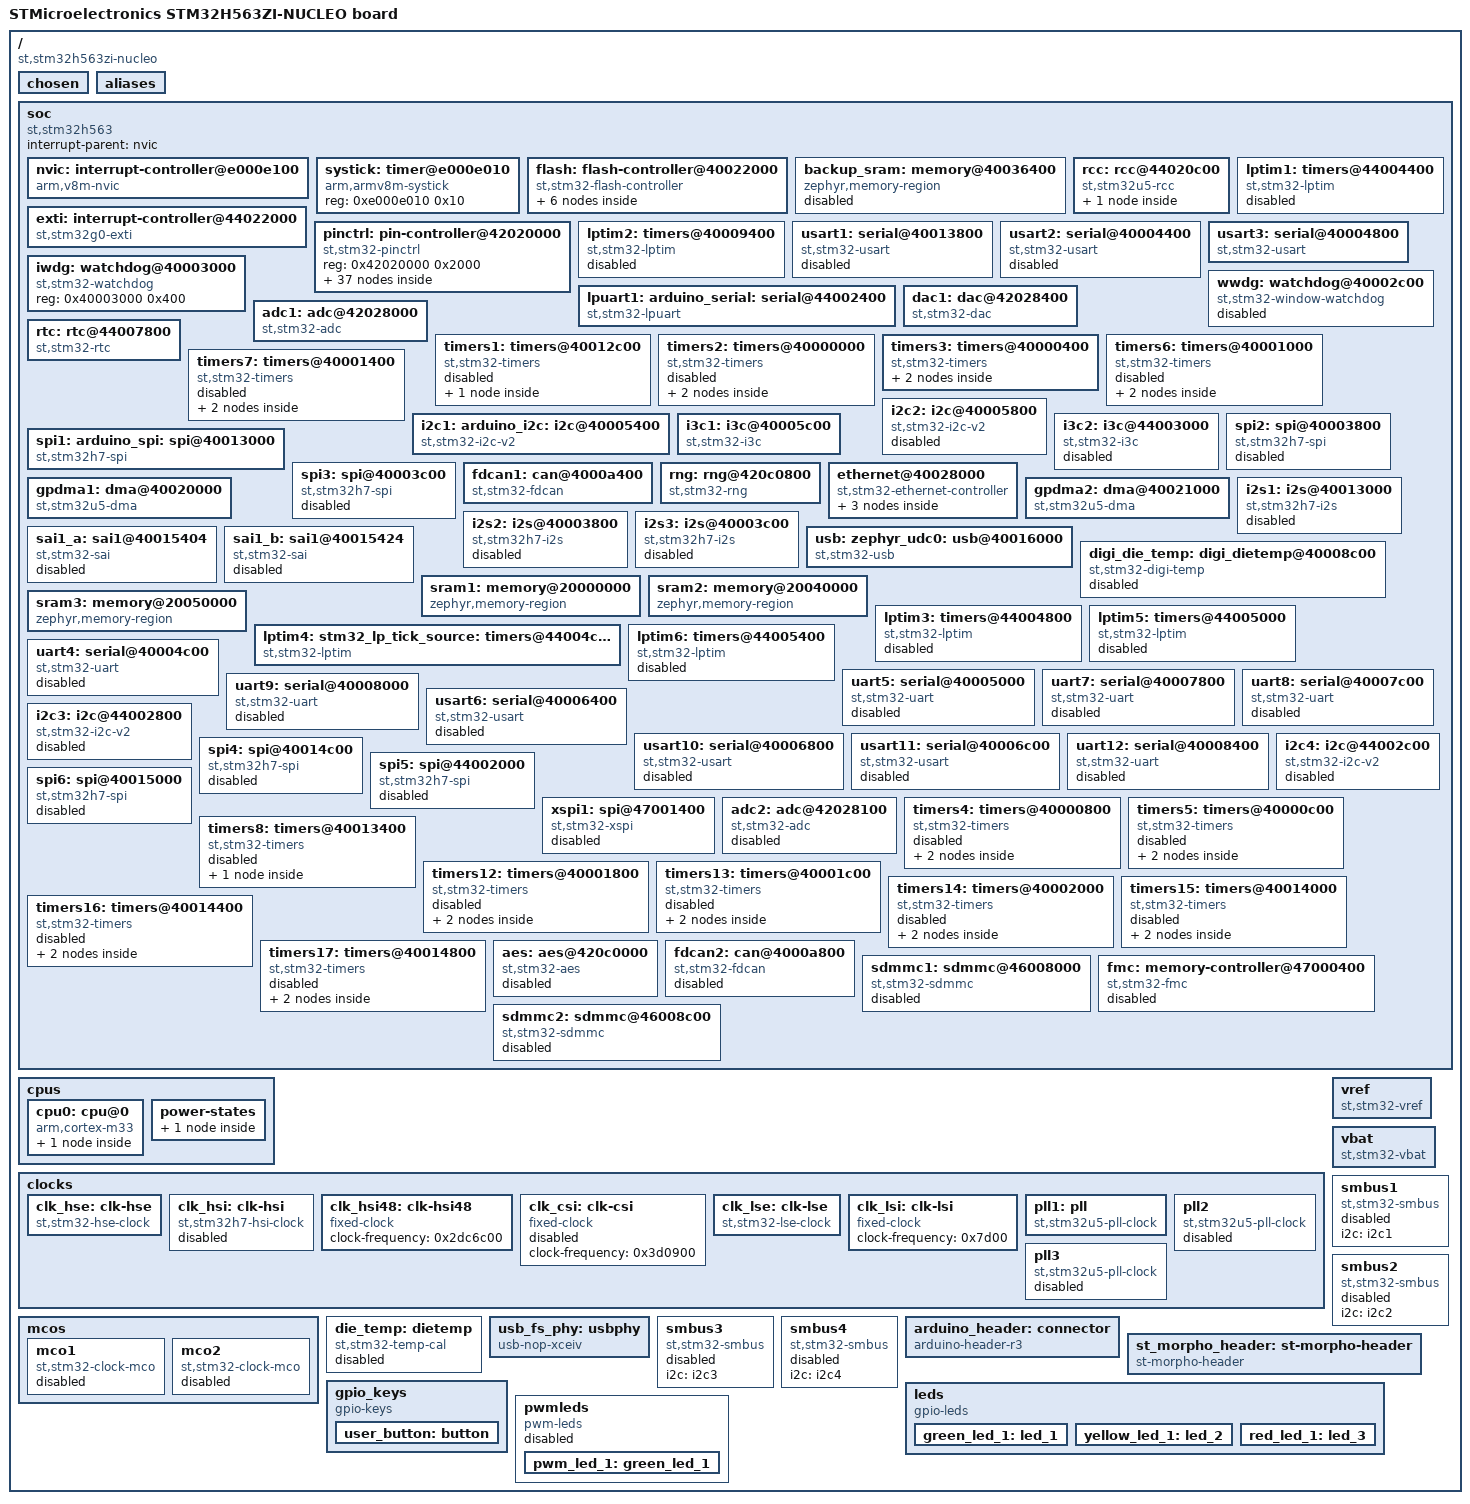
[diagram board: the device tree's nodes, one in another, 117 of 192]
/dts-v1/;

/* node '/' defined in zephyr/dts/common/skeleton.dtsi:9 */
/ {
	model = "STMicroelectronics STM32H563ZI-NUCLEO board"; /* in zephyr/boards/st/nucleo_h563zi/nucleo_h563zi.dts:13 */
	compatible = "st,stm32h563zi-nucleo";                  /* in zephyr/boards/st/nucleo_h563zi/nucleo_h563zi.dts:14 */
	#address-cells = < 0x1 >;                              /* in zephyr/boards/st/nucleo_h563zi/nucleo_h563zi.dts:16 */
	#size-cells = < 0x1 >;                                 /* in zephyr/boards/st/nucleo_h563zi/nucleo_h563zi.dts:17 */

	/* node '/chosen' defined in zephyr/dts/common/skeleton.dtsi:12 */
	chosen {
		zephyr,flash-controller = &flash;         /* in zephyr/dts/arm/st/h5/stm32h5.dtsi:21 */
		zephyr,entropy = &rng;                    /* in zephyr/dts/arm/st/h5/stm32h5.dtsi:22 */
		zephyr,console = &usart3;                 /* in zephyr/boards/st/nucleo_h563zi/nucleo_h563zi.dts:20 */
		zephyr,shell-uart = &usart3;              /* in zephyr/boards/st/nucleo_h563zi/nucleo_h563zi.dts:21 */
		zephyr,sram = &sram1;                     /* in zephyr/boards/st/nucleo_h563zi/nucleo_h563zi.dts:22 */
		zephyr,flash = &flash0;                   /* in zephyr/boards/st/nucleo_h563zi/nucleo_h563zi.dts:23 */
		zephyr,code-partition = &slot0_partition; /* in zephyr/boards/st/nucleo_h563zi/nucleo_h563zi.dts:24 */
		zephyr,canbus = &fdcan1;                  /* in zephyr/boards/st/nucleo_h563zi/nucleo_h563zi.dts:25 */
	};

	/* node '/aliases' defined in zephyr/dts/common/skeleton.dtsi:13 */
	aliases {
		led0 = &green_led_1;   /* in zephyr/boards/st/nucleo_h563zi/nucleo_h563zi.dts:29 */
		sw0 = &user_button;    /* in zephyr/boards/st/nucleo_h563zi/nucleo_h563zi.dts:30 */
		watchdog0 = &iwdg;     /* in zephyr/boards/st/nucleo_h563zi/nucleo_h563zi.dts:31 */
		pwm-led0 = &pwm_led_1; /* in zephyr/boards/st/nucleo_h563zi/nucleo_h563zi.dts:32 */
		volt-sensor0 = &vref;  /* in zephyr/boards/st/nucleo_h563zi/nucleo_h563zi.dts:33 */
		volt-sensor1 = &vbat;  /* in zephyr/boards/st/nucleo_h563zi/nucleo_h563zi.dts:34 */
	};

	/* node '/soc' defined in zephyr/dts/arm/armv8-m.dtsi:6 */
	soc {
		#address-cells = < 0x1 >;     /* in zephyr/dts/arm/armv8-m.dtsi:7 */
		#size-cells = < 0x1 >;        /* in zephyr/dts/arm/armv8-m.dtsi:8 */
		interrupt-parent = < &nvic >; /* in zephyr/dts/arm/armv8-m.dtsi:10 */
		ranges;                       /* in zephyr/dts/arm/armv8-m.dtsi:11 */
		compatible = "st,stm32h563",
		             "st,stm32h5",
		             "simple-bus";    /* in zephyr/dts/arm/st/h5/stm32h563.dtsi:11 */

		/* node '/soc/interrupt-controller@e000e100' defined in zephyr/dts/arm/armv8-m.dtsi:13 */
		nvic: interrupt-controller@e000e100 {
			#address-cells = < 0x1 >;            /* in zephyr/dts/arm/armv8-m.dtsi:14 */
			compatible = "arm,v8m-nvic";         /* in zephyr/dts/arm/armv8-m.dtsi:15 */
			reg = < 0xe000e100 0xc00 >;          /* in zephyr/dts/arm/armv8-m.dtsi:16 */
			interrupt-controller;                /* in zephyr/dts/arm/armv8-m.dtsi:17 */
			#interrupt-cells = < 0x2 >;          /* in zephyr/dts/arm/armv8-m.dtsi:18 */
			arm,num-irq-priority-bits = < 0x4 >; /* in zephyr/dts/arm/st/h5/stm32h5.dtsi:733 */
			phandle = < 0x1 >;                   /* in zephyr/dts/arm/armv8-m.dtsi:10 */
		};

		/* node '/soc/timer@e000e010' defined in zephyr/dts/arm/armv8-m.dtsi:21 */
		systick: timer@e000e010 {
			compatible = "arm,armv8m-systick"; /* in zephyr/dts/arm/armv8-m.dtsi:22 */
			reg = < 0xe000e010 0x10 >;         /* in zephyr/dts/arm/armv8-m.dtsi:23 */
		};

		/* node '/soc/flash-controller@40022000' defined in zephyr/dts/arm/st/h5/stm32h5.dtsi:123 */
		flash: flash-controller@40022000 {
			compatible = "st,stm32-flash-controller",
			             "st,stm32l5-flash-controller"; /* in zephyr/dts/arm/st/h5/stm32h5.dtsi:124 */
			reg = < 0x40022000 0x400 >;                 /* in zephyr/dts/arm/st/h5/stm32h5.dtsi:125 */
			interrupts = < 0x6 0x0 >;                   /* in zephyr/dts/arm/st/h5/stm32h5.dtsi:126 */
			#address-cells = < 0x1 >;                   /* in zephyr/dts/arm/st/h5/stm32h5.dtsi:128 */
			#size-cells = < 0x1 >;                      /* in zephyr/dts/arm/st/h5/stm32h5.dtsi:129 */

			/* node '/soc/flash-controller@40022000/flash@8000000' defined in zephyr/dts/arm/st/h5/stm32h5.dtsi:131 */
			flash0: flash@8000000 {
				compatible = "st,stm32-nv-flash",
				             "soc-nv-flash";      /* in zephyr/dts/arm/st/h5/stm32h5.dtsi:132 */
				write-block-size = < 0x10 >;      /* in zephyr/dts/arm/st/h5/stm32h5.dtsi:134 */
				erase-block-size = < 0x2000 >;    /* in zephyr/dts/arm/st/h5/stm32h5.dtsi:135 */
				max-erase-time = < 0xa >;         /* in zephyr/dts/arm/st/h5/stm32h5.dtsi:137 */
				reg = < 0x8000000 0x200000 >;     /* in zephyr/dts/arm/st/h5/stm32h563Xi.dtsi:14 */

				/* node '/soc/flash-controller@40022000/flash@8000000/partitions' defined in zephyr/boards/st/nucleo_h563zi/nucleo_h563zi-common.dtsi:178 */
				partitions {
					compatible = "fixed-partitions"; /* in zephyr/boards/st/nucleo_h563zi/nucleo_h563zi-common.dtsi:179 */
					#address-cells = < 0x1 >;        /* in zephyr/boards/st/nucleo_h563zi/nucleo_h563zi-common.dtsi:180 */
					#size-cells = < 0x1 >;           /* in zephyr/boards/st/nucleo_h563zi/nucleo_h563zi-common.dtsi:181 */

					/* node '/soc/flash-controller@40022000/flash@8000000/partitions/partition@0' defined in zephyr/boards/st/nucleo_h563zi/nucleo_h563zi-common.dtsi:183 */
					boot_partition: partition@0 {
						label = "mcuboot";     /* in zephyr/boards/st/nucleo_h563zi/nucleo_h563zi-common.dtsi:184 */
						reg = < 0x0 0x10000 >; /* in zephyr/boards/st/nucleo_h563zi/nucleo_h563zi-common.dtsi:185 */
					};

					/* node '/soc/flash-controller@40022000/flash@8000000/partitions/partition@10000' defined in zephyr/boards/st/nucleo_h563zi/nucleo_h563zi-common.dtsi:188 */
					slot0_partition: partition@10000 {
						label = "image-0";         /* in zephyr/boards/st/nucleo_h563zi/nucleo_h563zi-common.dtsi:189 */
						reg = < 0x10000 0xf0000 >; /* in zephyr/boards/st/nucleo_h563zi/nucleo_h563zi-common.dtsi:190 */
					};

					/* node '/soc/flash-controller@40022000/flash@8000000/partitions/partition@100000' defined in zephyr/boards/st/nucleo_h563zi/nucleo_h563zi-common.dtsi:193 */
					slot1_partition: partition@100000 {
						label = "image-1";          /* in zephyr/boards/st/nucleo_h563zi/nucleo_h563zi-common.dtsi:194 */
						reg = < 0x100000 0xf0000 >; /* in zephyr/boards/st/nucleo_h563zi/nucleo_h563zi-common.dtsi:195 */
					};

					/* node '/soc/flash-controller@40022000/flash@8000000/partitions/partition@1f0000' defined in zephyr/boards/st/nucleo_h563zi/nucleo_h563zi-common.dtsi:198 */
					storage_partition: partition@1f0000 {
						label = "storage";          /* in zephyr/boards/st/nucleo_h563zi/nucleo_h563zi-common.dtsi:199 */
						reg = < 0x1f0000 0x10000 >; /* in zephyr/boards/st/nucleo_h563zi/nucleo_h563zi-common.dtsi:200 */
					};
				};
			};
		};

		/* node '/soc/memory@40036400' defined in zephyr/dts/arm/st/h5/stm32h5.dtsi:141 */
		backup_sram: memory@40036400 {
			compatible = "zephyr,memory-region",
			             "st,stm32-backup-sram";  /* in zephyr/dts/arm/st/h5/stm32h5.dtsi:142 */
			clocks = < &rcc 0x88 0x10000000 >;    /* in zephyr/dts/arm/st/h5/stm32h5.dtsi:144 */
			zephyr,memory-region = "BACKUP_SRAM"; /* in zephyr/dts/arm/st/h5/stm32h5.dtsi:145 */
			status = "disabled";                  /* in zephyr/dts/arm/st/h5/stm32h5.dtsi:146 */
			reg = < 0x40036400 0x1000 >;          /* in zephyr/dts/arm/st/h5/stm32h562.dtsi:79 */
		};

		/* node '/soc/rcc@44020c00' defined in zephyr/dts/arm/st/h5/stm32h5.dtsi:149 */
		rcc: rcc@44020c00 {
			compatible = "st,stm32u5-rcc";   /* in zephyr/dts/arm/st/h5/stm32h5.dtsi:150 */
			clocks-controller;               /* in zephyr/dts/arm/st/h5/stm32h5.dtsi:151 */
			#clock-cells = < 0x2 >;          /* in zephyr/dts/arm/st/h5/stm32h5.dtsi:152 */
			reg = < 0x44020c00 0x400 >;      /* in zephyr/dts/arm/st/h5/stm32h5.dtsi:153 */
			clocks = < &pll >;               /* in zephyr/boards/st/nucleo_h563zi/nucleo_h563zi-common.dtsi:93 */
			clock-frequency = < 0xe4e1c00 >; /* in zephyr/boards/st/nucleo_h563zi/nucleo_h563zi-common.dtsi:94 */
			ahb-prescaler = < 0x1 >;         /* in zephyr/boards/st/nucleo_h563zi/nucleo_h563zi-common.dtsi:95 */
			apb1-prescaler = < 0x2 >;        /* in zephyr/boards/st/nucleo_h563zi/nucleo_h563zi-common.dtsi:96 */
			apb2-prescaler = < 0x1 >;        /* in zephyr/boards/st/nucleo_h563zi/nucleo_h563zi-common.dtsi:97 */
			apb3-prescaler = < 0x2 >;        /* in zephyr/boards/st/nucleo_h563zi/nucleo_h563zi-common.dtsi:98 */
			phandle = < 0x2 >;               /* in zephyr/dts/arm/st/h5/stm32h5.dtsi:144 */

			/* node '/soc/rcc@44020c00/reset-controller' defined in zephyr/dts/arm/st/h5/stm32h5.dtsi:155 */
			rctl: reset-controller {
				compatible = "st,stm32-rcc-rctl"; /* in zephyr/dts/arm/st/h5/stm32h5.dtsi:156 */
				#reset-cells = < 0x1 >;           /* in zephyr/dts/arm/st/h5/stm32h5.dtsi:157 */
				phandle = < 0x4 >;                /* in zephyr/dts/arm/st/h5/stm32h5.dtsi:256 */
			};
		};

		/* node '/soc/interrupt-controller@44022000' defined in zephyr/dts/arm/st/h5/stm32h5.dtsi:161 */
		exti: interrupt-controller@44022000 {
			compatible = "st,stm32g0-exti",
			             "st,stm32-exti";   /* in zephyr/dts/arm/st/h5/stm32h5.dtsi:162 */
			interrupt-controller;           /* in zephyr/dts/arm/st/h5/stm32h5.dtsi:163 */
			#interrupt-cells = < 0x1 >;     /* in zephyr/dts/arm/st/h5/stm32h5.dtsi:164 */
			#address-cells = < 0x1 >;       /* in zephyr/dts/arm/st/h5/stm32h5.dtsi:165 */
			reg = < 0x44022000 0x400 >;     /* in zephyr/dts/arm/st/h5/stm32h5.dtsi:166 */
			clocks = < &rcc 0xa8 0x2 >;     /* in zephyr/dts/arm/st/h5/stm32h5.dtsi:167 */
			num-lines = < 0x40 >;           /* in zephyr/dts/arm/st/h5/stm32h5.dtsi:168 */
			interrupts = < 0xb 0x0 >,
			             < 0xc 0x0 >,
			             < 0xd 0x0 >,
			             < 0xe 0x0 >,
			             < 0xf 0x0 >,
			             < 0x10 0x0 >,
			             < 0x11 0x0 >,
			             < 0x12 0x0 >,
			             < 0x13 0x0 >,
			             < 0x14 0x0 >,
			             < 0x15 0x0 >,
			             < 0x16 0x0 >,
			             < 0x17 0x0 >,
			             < 0x18 0x0 >,
			             < 0x19 0x0 >,
			             < 0x1a 0x0 >;      /* in zephyr/dts/arm/st/h5/stm32h5.dtsi:169 */
			interrupt-names = "line0",
			                  "line1",
			                  "line2",
			                  "line3",
			                  "line4",
			                  "line5",
			                  "line6",
			                  "line7",
			                  "line8",
			                  "line9",
			                  "line10",
			                  "line11",
			                  "line12",
			                  "line13",
			                  "line14",
			                  "line15";     /* in zephyr/dts/arm/st/h5/stm32h5.dtsi:173 */
			line-ranges = < 0x0 0x1 >,
			              < 0x1 0x1 >,
			              < 0x2 0x1 >,
			              < 0x3 0x1 >,
			              < 0x4 0x1 >,
			              < 0x5 0x1 >,
			              < 0x6 0x1 >,
			              < 0x7 0x1 >,
			              < 0x8 0x1 >,
			              < 0x9 0x1 >,
			              < 0xa 0x1 >,
			              < 0xb 0x1 >,
			              < 0xc 0x1 >,
			              < 0xd 0x1 >,
			              < 0xe 0x1 >,
			              < 0xf 0x1 >;      /* in zephyr/dts/arm/st/h5/stm32h5.dtsi:177 */
		};

		/* node '/soc/pin-controller@42020000' defined in zephyr/dts/arm/st/h5/stm32h5.dtsi:183 */
		pinctrl: pin-controller@42020000 {
			compatible = "st,stm32-pinctrl"; /* in zephyr/dts/arm/st/h5/stm32h5.dtsi:184 */
			#address-cells = < 0x1 >;        /* in zephyr/dts/arm/st/h5/stm32h5.dtsi:185 */
			#size-cells = < 0x1 >;           /* in zephyr/dts/arm/st/h5/stm32h5.dtsi:186 */
			reg = < 0x42020000 0x2000 >;     /* in zephyr/dts/arm/st/h5/stm32h5.dtsi:187 */

			/* node '/soc/pin-controller@42020000/gpio@42020000' defined in zephyr/dts/arm/st/h5/stm32h5.dtsi:189 */
			gpioa: gpio@42020000 {
				compatible = "st,stm32-gpio"; /* in zephyr/dts/arm/st/h5/stm32h5.dtsi:190 */
				gpio-controller;              /* in zephyr/dts/arm/st/h5/stm32h5.dtsi:191 */
				#gpio-cells = < 0x2 >;        /* in zephyr/dts/arm/st/h5/stm32h5.dtsi:192 */
				reg = < 0x42020000 0x400 >;   /* in zephyr/dts/arm/st/h5/stm32h5.dtsi:193 */
				clocks = < &rcc 0x8c 0x1 >;   /* in zephyr/dts/arm/st/h5/stm32h5.dtsi:194 */
				phandle = < 0x2c >;           /* in zephyr/boards/st/nucleo_h563zi/arduino_r3_connector.dtsi:14 */
			};

			/* node '/soc/pin-controller@42020000/gpio@42020400' defined in zephyr/dts/arm/st/h5/stm32h5.dtsi:197 */
			gpiob: gpio@42020400 {
				compatible = "st,stm32-gpio"; /* in zephyr/dts/arm/st/h5/stm32h5.dtsi:198 */
				gpio-controller;              /* in zephyr/dts/arm/st/h5/stm32h5.dtsi:199 */
				#gpio-cells = < 0x2 >;        /* in zephyr/dts/arm/st/h5/stm32h5.dtsi:200 */
				reg = < 0x42020400 0x400 >;   /* in zephyr/dts/arm/st/h5/stm32h5.dtsi:201 */
				clocks = < &rcc 0x8c 0x2 >;   /* in zephyr/dts/arm/st/h5/stm32h5.dtsi:202 */
				phandle = < 0x2e >;           /* in zephyr/boards/st/nucleo_h563zi/arduino_r3_connector.dtsi:14 */
			};

			/* node '/soc/pin-controller@42020000/gpio@42020800' defined in zephyr/dts/arm/st/h5/stm32h5.dtsi:205 */
			gpioc: gpio@42020800 {
				compatible = "st,stm32-gpio"; /* in zephyr/dts/arm/st/h5/stm32h5.dtsi:206 */
				gpio-controller;              /* in zephyr/dts/arm/st/h5/stm32h5.dtsi:207 */
				#gpio-cells = < 0x2 >;        /* in zephyr/dts/arm/st/h5/stm32h5.dtsi:208 */
				reg = < 0x42020800 0x400 >;   /* in zephyr/dts/arm/st/h5/stm32h5.dtsi:209 */
				clocks = < &rcc 0x8c 0x4 >;   /* in zephyr/dts/arm/st/h5/stm32h5.dtsi:210 */
				phandle = < 0x2d >;           /* in zephyr/boards/st/nucleo_h563zi/arduino_r3_connector.dtsi:14 */
			};

			/* node '/soc/pin-controller@42020000/gpio@42020c00' defined in zephyr/dts/arm/st/h5/stm32h5.dtsi:213 */
			gpiod: gpio@42020c00 {
				compatible = "st,stm32-gpio"; /* in zephyr/dts/arm/st/h5/stm32h5.dtsi:214 */
				gpio-controller;              /* in zephyr/dts/arm/st/h5/stm32h5.dtsi:215 */
				#gpio-cells = < 0x2 >;        /* in zephyr/dts/arm/st/h5/stm32h5.dtsi:216 */
				reg = < 0x42020c00 0x400 >;   /* in zephyr/dts/arm/st/h5/stm32h5.dtsi:217 */
				clocks = < &rcc 0x8c 0x8 >;   /* in zephyr/dts/arm/st/h5/stm32h5.dtsi:218 */
				phandle = < 0x14 >;           /* in zephyr/boards/st/nucleo_h563zi/nucleo_h563zi-common.dtsi:118 */
			};

			/* node '/soc/pin-controller@42020000/gpio@42021c00' defined in zephyr/dts/arm/st/h5/stm32h5.dtsi:221 */
			gpioh: gpio@42021c00 {
				compatible = "st,stm32-gpio"; /* in zephyr/dts/arm/st/h5/stm32h5.dtsi:222 */
				gpio-controller;              /* in zephyr/dts/arm/st/h5/stm32h5.dtsi:223 */
				#gpio-cells = < 0x2 >;        /* in zephyr/dts/arm/st/h5/stm32h5.dtsi:224 */
				reg = < 0x42021c00 0x400 >;   /* in zephyr/dts/arm/st/h5/stm32h5.dtsi:225 */
				clocks = < &rcc 0x8c 0x80 >;  /* in zephyr/dts/arm/st/h5/stm32h5.dtsi:226 */
				phandle = < 0x32 >;           /* in zephyr/boards/st/nucleo_h563zi/st_morpho_connector.dtsi:15 */
			};

			/* node '/soc/pin-controller@42020000/gpio@42021000' defined in zephyr/dts/arm/st/h5/stm32h562.dtsi:27 */
			gpioe: gpio@42021000 {
				compatible = "st,stm32-gpio"; /* in zephyr/dts/arm/st/h5/stm32h562.dtsi:28 */
				gpio-controller;              /* in zephyr/dts/arm/st/h5/stm32h562.dtsi:29 */
				#gpio-cells = < 0x2 >;        /* in zephyr/dts/arm/st/h5/stm32h562.dtsi:30 */
				reg = < 0x42021000 0x400 >;   /* in zephyr/dts/arm/st/h5/stm32h562.dtsi:31 */
				clocks = < &rcc 0x8c 0x10 >;  /* in zephyr/dts/arm/st/h5/stm32h562.dtsi:32 */
				phandle = < 0x31 >;           /* in zephyr/boards/st/nucleo_h563zi/arduino_r3_connector.dtsi:14 */
			};

			/* node '/soc/pin-controller@42020000/gpio@42021400' defined in zephyr/dts/arm/st/h5/stm32h562.dtsi:35 */
			gpiof: gpio@42021400 {
				compatible = "st,stm32-gpio"; /* in zephyr/dts/arm/st/h5/stm32h562.dtsi:36 */
				gpio-controller;              /* in zephyr/dts/arm/st/h5/stm32h562.dtsi:37 */
				#gpio-cells = < 0x2 >;        /* in zephyr/dts/arm/st/h5/stm32h562.dtsi:38 */
				reg = < 0x42021400 0x400 >;   /* in zephyr/dts/arm/st/h5/stm32h562.dtsi:39 */
				clocks = < &rcc 0x8c 0x20 >;  /* in zephyr/dts/arm/st/h5/stm32h562.dtsi:40 */
				phandle = < 0x2f >;           /* in zephyr/boards/st/nucleo_h563zi/arduino_r3_connector.dtsi:14 */
			};

			/* node '/soc/pin-controller@42020000/gpio@42021800' defined in zephyr/dts/arm/st/h5/stm32h562.dtsi:43 */
			gpiog: gpio@42021800 {
				compatible = "st,stm32-gpio"; /* in zephyr/dts/arm/st/h5/stm32h562.dtsi:44 */
				gpio-controller;              /* in zephyr/dts/arm/st/h5/stm32h562.dtsi:45 */
				#gpio-cells = < 0x2 >;        /* in zephyr/dts/arm/st/h5/stm32h562.dtsi:46 */
				reg = < 0x42021800 0x400 >;   /* in zephyr/dts/arm/st/h5/stm32h562.dtsi:47 */
				clocks = < &rcc 0x8c 0x40 >;  /* in zephyr/dts/arm/st/h5/stm32h562.dtsi:48 */
				phandle = < 0x30 >;           /* in zephyr/boards/st/nucleo_h563zi/arduino_r3_connector.dtsi:14 */
			};

			/* node '/soc/pin-controller@42020000/gpio@42022000' defined in zephyr/dts/arm/st/h5/stm32h562.dtsi:51 */
			gpioi: gpio@42022000 {
				compatible = "st,stm32-gpio"; /* in zephyr/dts/arm/st/h5/stm32h562.dtsi:52 */
				gpio-controller;              /* in zephyr/dts/arm/st/h5/stm32h562.dtsi:53 */
				#gpio-cells = < 0x2 >;        /* in zephyr/dts/arm/st/h5/stm32h562.dtsi:54 */
				reg = < 0x42022000 0x400 >;   /* in zephyr/dts/arm/st/h5/stm32h562.dtsi:55 */
				clocks = < &rcc 0x8c 0x100 >; /* in zephyr/dts/arm/st/h5/stm32h562.dtsi:56 */
			};

			/* node '/soc/pin-controller@42020000/adc1_inp15_pa3' defined in modules/hal/stm32/dts/st/h5/stm32h563zitx-pinctrl.dtsi:31 */
			adc1_inp15_pa3: adc1_inp15_pa3 {
				pinmux = < 0x70 >; /* in modules/hal/stm32/dts/st/h5/stm32h563zitx-pinctrl.dtsi:32 */
				phandle = < 0xb >; /* in zephyr/boards/st/nucleo_h563zi/nucleo_h563zi-common.dtsi:161 */
			};

			/* node '/soc/pin-controller@42020000/adc1_inp3_pa6' defined in modules/hal/stm32/dts/st/h5/stm32h563zitx-pinctrl.dtsi:47 */
			adc1_inp3_pa6: adc1_inp3_pa6 {
				pinmux = < 0xd0 >; /* in modules/hal/stm32/dts/st/h5/stm32h563zitx-pinctrl.dtsi:48 */
				phandle = < 0xa >; /* in zephyr/boards/st/nucleo_h563zi/nucleo_h563zi-common.dtsi:161 */
			};

			/* node '/soc/pin-controller@42020000/dac1_out2_pa5' defined in modules/hal/stm32/dts/st/h5/stm32h563zitx-pinctrl.dtsi:687 */
			dac1_out2_pa5: dac1_out2_pa5 {
				pinmux = < 0xb0 >; /* in modules/hal/stm32/dts/st/h5/stm32h563zitx-pinctrl.dtsi:688 */
				phandle = < 0x9 >; /* in zephyr/boards/st/nucleo_h563zi/nucleo_h563zi-common.dtsi:153 */
			};

			/* node '/soc/pin-controller@42020000/eth_ref_clk_pa1' defined in modules/hal/stm32/dts/st/h5/stm32h563zitx-pinctrl.dtsi:895 */
			eth_ref_clk_pa1: eth_ref_clk_pa1 {
				pinmux = < 0x2b >;             /* in modules/hal/stm32/dts/st/h5/stm32h563zitx-pinctrl.dtsi:896 */
				slew-rate = "very-high-speed"; /* in modules/hal/stm32/dts/st/h5/stm32h563zitx-pinctrl.dtsi:897 */
				phandle = < 0x19 >;            /* in zephyr/boards/st/nucleo_h563zi/nucleo_h563zi.dts:44 */
			};

			/* node '/soc/pin-controller@42020000/eth_mdio_pa2' defined in modules/hal/stm32/dts/st/h5/stm32h563zitx-pinctrl.dtsi:905 */
			eth_mdio_pa2: eth_mdio_pa2 {
				pinmux = < 0x4b >;             /* in modules/hal/stm32/dts/st/h5/stm32h563zitx-pinctrl.dtsi:906 */
				slew-rate = "very-high-speed"; /* in modules/hal/stm32/dts/st/h5/stm32h563zitx-pinctrl.dtsi:907 */
				phandle = < 0x1f >;            /* in zephyr/boards/st/nucleo_h563zi/nucleo_h563zi.dts:58 */
			};

			/* node '/soc/pin-controller@42020000/eth_crs_dv_pa7' defined in modules/hal/stm32/dts/st/h5/stm32h563zitx-pinctrl.dtsi:920 */
			eth_crs_dv_pa7: eth_crs_dv_pa7 {
				pinmux = < 0xeb >;             /* in modules/hal/stm32/dts/st/h5/stm32h563zitx-pinctrl.dtsi:921 */
				slew-rate = "very-high-speed"; /* in modules/hal/stm32/dts/st/h5/stm32h563zitx-pinctrl.dtsi:922 */
				phandle = < 0x1a >;            /* in zephyr/boards/st/nucleo_h563zi/nucleo_h563zi.dts:44 */
			};

			/* node '/soc/pin-controller@42020000/eth_txd1_pb15' defined in modules/hal/stm32/dts/st/h5/stm32h563zitx-pinctrl.dtsi:960 */
			eth_txd1_pb15: eth_txd1_pb15 {
				pinmux = < 0x3eb >;            /* in modules/hal/stm32/dts/st/h5/stm32h563zitx-pinctrl.dtsi:961 */
				slew-rate = "very-high-speed"; /* in modules/hal/stm32/dts/st/h5/stm32h563zitx-pinctrl.dtsi:962 */
				phandle = < 0x1d >;            /* in zephyr/boards/st/nucleo_h563zi/nucleo_h563zi.dts:44 */
			};

			/* node '/soc/pin-controller@42020000/eth_mdc_pc1' defined in modules/hal/stm32/dts/st/h5/stm32h563zitx-pinctrl.dtsi:965 */
			eth_mdc_pc1: eth_mdc_pc1 {
				pinmux = < 0x42b >;            /* in modules/hal/stm32/dts/st/h5/stm32h563zitx-pinctrl.dtsi:966 */
				slew-rate = "very-high-speed"; /* in modules/hal/stm32/dts/st/h5/stm32h563zitx-pinctrl.dtsi:967 */
				phandle = < 0x20 >;            /* in zephyr/boards/st/nucleo_h563zi/nucleo_h563zi.dts:58 */
			};

			/* node '/soc/pin-controller@42020000/eth_rxd0_pc4' defined in modules/hal/stm32/dts/st/h5/stm32h563zitx-pinctrl.dtsi:980 */
			eth_rxd0_pc4: eth_rxd0_pc4 {
				pinmux = < 0x48b >;            /* in modules/hal/stm32/dts/st/h5/stm32h563zitx-pinctrl.dtsi:981 */
				slew-rate = "very-high-speed"; /* in modules/hal/stm32/dts/st/h5/stm32h563zitx-pinctrl.dtsi:982 */
				phandle = < 0x17 >;            /* in zephyr/boards/st/nucleo_h563zi/nucleo_h563zi.dts:44 */
			};

			/* node '/soc/pin-controller@42020000/eth_rxd1_pc5' defined in modules/hal/stm32/dts/st/h5/stm32h563zitx-pinctrl.dtsi:985 */
			eth_rxd1_pc5: eth_rxd1_pc5 {
				pinmux = < 0x4ab >;            /* in modules/hal/stm32/dts/st/h5/stm32h563zitx-pinctrl.dtsi:986 */
				slew-rate = "very-high-speed"; /* in modules/hal/stm32/dts/st/h5/stm32h563zitx-pinctrl.dtsi:987 */
				phandle = < 0x18 >;            /* in zephyr/boards/st/nucleo_h563zi/nucleo_h563zi.dts:44 */
			};

			/* node '/soc/pin-controller@42020000/eth_tx_en_pg11' defined in modules/hal/stm32/dts/st/h5/stm32h563zitx-pinctrl.dtsi:1005 */
			eth_tx_en_pg11: eth_tx_en_pg11 {
				pinmux = < 0xd6b >;            /* in modules/hal/stm32/dts/st/h5/stm32h563zitx-pinctrl.dtsi:1006 */
				slew-rate = "very-high-speed"; /* in modules/hal/stm32/dts/st/h5/stm32h563zitx-pinctrl.dtsi:1007 */
				phandle = < 0x1b >;            /* in zephyr/boards/st/nucleo_h563zi/nucleo_h563zi.dts:44 */
			};

			/* node '/soc/pin-controller@42020000/eth_txd0_pg13' defined in modules/hal/stm32/dts/st/h5/stm32h563zitx-pinctrl.dtsi:1015 */
			eth_txd0_pg13: eth_txd0_pg13 {
				pinmux = < 0xdab >;            /* in modules/hal/stm32/dts/st/h5/stm32h563zitx-pinctrl.dtsi:1016 */
				slew-rate = "very-high-speed"; /* in modules/hal/stm32/dts/st/h5/stm32h563zitx-pinctrl.dtsi:1017 */
				phandle = < 0x1c >;            /* in zephyr/boards/st/nucleo_h563zi/nucleo_h563zi.dts:44 */
			};

			/* node '/soc/pin-controller@42020000/fdcan1_rx_pd0' defined in modules/hal/stm32/dts/st/h5/stm32h563zitx-pinctrl.dtsi:1035 */
			fdcan1_rx_pd0: fdcan1_rx_pd0 {
				pinmux = < 0x609 >; /* in modules/hal/stm32/dts/st/h5/stm32h563zitx-pinctrl.dtsi:1036 */
				phandle = < 0x15 >; /* in zephyr/boards/st/nucleo_h563zi/nucleo_h563zi-common.dtsi:169 */
			};

			/* node '/soc/pin-controller@42020000/fdcan1_tx_pd1' defined in modules/hal/stm32/dts/st/h5/stm32h563zitx-pinctrl.dtsi:1069 */
			fdcan1_tx_pd1: fdcan1_tx_pd1 {
				pinmux = < 0x629 >; /* in modules/hal/stm32/dts/st/h5/stm32h563zitx-pinctrl.dtsi:1070 */
				phandle = < 0x16 >; /* in zephyr/boards/st/nucleo_h563zi/nucleo_h563zi-common.dtsi:169 */
			};

			/* node '/soc/pin-controller@42020000/i2c1_scl_pb8' defined in modules/hal/stm32/dts/st/h5/stm32h563zitx-pinctrl.dtsi:1561 */
			i2c1_scl_pb8: i2c1_scl_pb8 {
				pinmux = < 0x304 >; /* in modules/hal/stm32/dts/st/h5/stm32h563zitx-pinctrl.dtsi:1562 */
				bias-pull-up;       /* in modules/hal/stm32/dts/st/h5/stm32h563zitx-pinctrl.dtsi:1563 */
				drive-open-drain;   /* in modules/hal/stm32/dts/st/h5/stm32h563zitx-pinctrl.dtsi:1564 */
				phandle = < 0xd >;  /* in zephyr/boards/st/nucleo_h563zi/nucleo_h563zi-common.dtsi:80 */
			};

			/* node '/soc/pin-controller@42020000/i2c1_sda_pb9' defined in modules/hal/stm32/dts/st/h5/stm32h563zitx-pinctrl.dtsi:1623 */
			i2c1_sda_pb9: i2c1_sda_pb9 {
				pinmux = < 0x324 >; /* in modules/hal/stm32/dts/st/h5/stm32h563zitx-pinctrl.dtsi:1624 */
				bias-pull-up;       /* in modules/hal/stm32/dts/st/h5/stm32h563zitx-pinctrl.dtsi:1625 */
				drive-open-drain;   /* in modules/hal/stm32/dts/st/h5/stm32h563zitx-pinctrl.dtsi:1626 */
				phandle = < 0xe >;  /* in zephyr/boards/st/nucleo_h563zi/nucleo_h563zi-common.dtsi:80 */
			};

			/* node '/soc/pin-controller@42020000/i3c1_scl_pd12' defined in modules/hal/stm32/dts/st/h5/stm32h563zitx-pinctrl.dtsi:1843 */
			i3c1_scl_pd12: i3c1_scl_pd12 {
				pinmux = < 0x785 >;            /* in modules/hal/stm32/dts/st/h5/stm32h563zitx-pinctrl.dtsi:1844 */
				slew-rate = "very-high-speed"; /* in modules/hal/stm32/dts/st/h5/stm32h563zitx-pinctrl.dtsi:1845 */
				phandle = < 0xf >;             /* in zephyr/boards/st/nucleo_h563zi/nucleo_h563zi-common.dtsi:86 */
			};

			/* node '/soc/pin-controller@42020000/i3c1_sda_pd13' defined in modules/hal/stm32/dts/st/h5/stm32h563zitx-pinctrl.dtsi:1870 */
			i3c1_sda_pd13: i3c1_sda_pd13 {
				pinmux = < 0x7a5 >;            /* in modules/hal/stm32/dts/st/h5/stm32h563zitx-pinctrl.dtsi:1871 */
				slew-rate = "very-high-speed"; /* in modules/hal/stm32/dts/st/h5/stm32h563zitx-pinctrl.dtsi:1872 */
				phandle = < 0x10 >;            /* in zephyr/boards/st/nucleo_h563zi/nucleo_h563zi-common.dtsi:86 */
			};

			/* node '/soc/pin-controller@42020000/spi1_miso_pg9' defined in modules/hal/stm32/dts/st/h5/stm32h563zitx-pinctrl.dtsi:2606 */
			spi1_miso_pg9: spi1_miso_pg9 {
				pinmux = < 0xd25 >; /* in modules/hal/stm32/dts/st/h5/stm32h563zitx-pinctrl.dtsi:2607 */
				bias-pull-down;     /* in modules/hal/stm32/dts/st/h5/stm32h563zitx-pinctrl.dtsi:2608 */
				phandle = < 0x12 >; /* in zephyr/boards/st/nucleo_h563zi/nucleo_h563zi-common.dtsi:116 */
			};

			/* node '/soc/pin-controller@42020000/spi1_mosi_pb5' defined in modules/hal/stm32/dts/st/h5/stm32h563zitx-pinctrl.dtsi:2668 */
			spi1_mosi_pb5: spi1_mosi_pb5 {
				pinmux = < 0x2a5 >; /* in modules/hal/stm32/dts/st/h5/stm32h563zitx-pinctrl.dtsi:2669 */
				bias-pull-down;     /* in modules/hal/stm32/dts/st/h5/stm32h563zitx-pinctrl.dtsi:2670 */
				phandle = < 0x13 >; /* in zephyr/boards/st/nucleo_h563zi/nucleo_h563zi-common.dtsi:116 */
			};

			/* node '/soc/pin-controller@42020000/spi1_sck_pa5' defined in modules/hal/stm32/dts/st/h5/stm32h563zitx-pinctrl.dtsi:2842 */
			spi1_sck_pa5: spi1_sck_pa5 {
				pinmux = < 0xa5 >;             /* in modules/hal/stm32/dts/st/h5/stm32h563zitx-pinctrl.dtsi:2843 */
				bias-pull-down;                /* in modules/hal/stm32/dts/st/h5/stm32h563zitx-pinctrl.dtsi:2844 */
				slew-rate = "very-high-speed"; /* in modules/hal/stm32/dts/st/h5/stm32h563zitx-pinctrl.dtsi:2845 */
				phandle = < 0x11 >;            /* in zephyr/boards/st/nucleo_h563zi/nucleo_h563zi-common.dtsi:116 */
			};

			/* node '/soc/pin-controller@42020000/tim3_ch3_pb0' defined in modules/hal/stm32/dts/st/h5/stm32h563zitx-pinctrl.dtsi:3152 */
			tim3_ch3_pb0: tim3_ch3_pb0 {
				pinmux = < 0x202 >; /* in modules/hal/stm32/dts/st/h5/stm32h563zitx-pinctrl.dtsi:3153 */
				phandle = < 0xc >;  /* in zephyr/boards/st/nucleo_h563zi/nucleo_h563zi-common.dtsi:128 */
			};

			/* node '/soc/pin-controller@42020000/lpuart1_rx_pb7' defined in modules/hal/stm32/dts/st/h5/stm32h563zitx-pinctrl.dtsi:3688 */
			lpuart1_rx_pb7: lpuart1_rx_pb7 {
				pinmux = < 0x2e8 >; /* in modules/hal/stm32/dts/st/h5/stm32h563zitx-pinctrl.dtsi:3689 */
				phandle = < 0x8 >;  /* in zephyr/boards/st/nucleo_h563zi/nucleo_h563zi-common.dtsi:102 */
			};

			/* node '/soc/pin-controller@42020000/usart3_rx_pd9' defined in modules/hal/stm32/dts/st/h5/stm32h563zitx-pinctrl.dtsi:3732 */
			usart3_rx_pd9: usart3_rx_pd9 {
				pinmux = < 0x727 >; /* in modules/hal/stm32/dts/st/h5/stm32h563zitx-pinctrl.dtsi:3733 */
				phandle = < 0x6 >;  /* in zephyr/boards/st/nucleo_h563zi/nucleo_h563zi-common.dtsi:109 */
			};

			/* node '/soc/pin-controller@42020000/lpuart1_tx_pb6' defined in modules/hal/stm32/dts/st/h5/stm32h563zitx-pinctrl.dtsi:3839 */
			lpuart1_tx_pb6: lpuart1_tx_pb6 {
				pinmux = < 0x2c8 >; /* in modules/hal/stm32/dts/st/h5/stm32h563zitx-pinctrl.dtsi:3840 */
				bias-pull-up;       /* in modules/hal/stm32/dts/st/h5/stm32h563zitx-pinctrl.dtsi:3841 */
				phandle = < 0x7 >;  /* in zephyr/boards/st/nucleo_h563zi/nucleo_h563zi-common.dtsi:102 */
			};

			/* node '/soc/pin-controller@42020000/usart3_tx_pd8' defined in modules/hal/stm32/dts/st/h5/stm32h563zitx-pinctrl.dtsi:3894 */
			usart3_tx_pd8: usart3_tx_pd8 {
				pinmux = < 0x707 >; /* in modules/hal/stm32/dts/st/h5/stm32h563zitx-pinctrl.dtsi:3895 */
				bias-pull-up;       /* in modules/hal/stm32/dts/st/h5/stm32h563zitx-pinctrl.dtsi:3896 */
				phandle = < 0x5 >;  /* in zephyr/boards/st/nucleo_h563zi/nucleo_h563zi-common.dtsi:109 */
			};

			/* node '/soc/pin-controller@42020000/usb_dm_pa11' defined in modules/hal/stm32/dts/st/h5/stm32h563zitx-pinctrl.dtsi:4001 */
			usb_dm_pa11: usb_dm_pa11 {
				pinmux = < 0x16a >; /* in modules/hal/stm32/dts/st/h5/stm32h563zitx-pinctrl.dtsi:4002 */
				phandle = < 0x23 >; /* in zephyr/boards/st/nucleo_h563zi/nucleo_h563zi-common.dtsi:206 */
			};

			/* node '/soc/pin-controller@42020000/usb_dp_pa12' defined in modules/hal/stm32/dts/st/h5/stm32h563zitx-pinctrl.dtsi:4005 */
			usb_dp_pa12: usb_dp_pa12 {
				pinmux = < 0x18a >; /* in modules/hal/stm32/dts/st/h5/stm32h563zitx-pinctrl.dtsi:4006 */
				phandle = < 0x24 >; /* in zephyr/boards/st/nucleo_h563zi/nucleo_h563zi-common.dtsi:206 */
			};
		};

		/* node '/soc/timers@44004400' defined in zephyr/dts/arm/st/h5/stm32h5.dtsi:230 */
		lptim1: timers@44004400 {
			compatible = "st,stm32-lptim"; /* in zephyr/dts/arm/st/h5/stm32h5.dtsi:231 */
			clocks = < &rcc 0xa8 0x800 >;  /* in zephyr/dts/arm/st/h5/stm32h5.dtsi:232 */
			#address-cells = < 0x1 >;      /* in zephyr/dts/arm/st/h5/stm32h5.dtsi:233 */
			#size-cells = < 0x0 >;         /* in zephyr/dts/arm/st/h5/stm32h5.dtsi:234 */
			reg = < 0x44004400 0x400 >;    /* in zephyr/dts/arm/st/h5/stm32h5.dtsi:235 */
			interrupts = < 0x40 0x1 >;     /* in zephyr/dts/arm/st/h5/stm32h5.dtsi:236 */
			interrupt-names = "wakeup";    /* in zephyr/dts/arm/st/h5/stm32h5.dtsi:237 */
			status = "disabled";           /* in zephyr/dts/arm/st/h5/stm32h5.dtsi:238 */
		};

		/* node '/soc/timers@40009400' defined in zephyr/dts/arm/st/h5/stm32h5.dtsi:241 */
		lptim2: timers@40009400 {
			compatible = "st,stm32-lptim"; /* in zephyr/dts/arm/st/h5/stm32h5.dtsi:242 */
			clocks = < &rcc 0xa0 0x20 >;   /* in zephyr/dts/arm/st/h5/stm32h5.dtsi:243 */
			#address-cells = < 0x1 >;      /* in zephyr/dts/arm/st/h5/stm32h5.dtsi:244 */
			#size-cells = < 0x0 >;         /* in zephyr/dts/arm/st/h5/stm32h5.dtsi:245 */
			reg = < 0x40009400 0x400 >;    /* in zephyr/dts/arm/st/h5/stm32h5.dtsi:246 */
			interrupts = < 0x46 0x1 >;     /* in zephyr/dts/arm/st/h5/stm32h5.dtsi:247 */
			interrupt-names = "wakeup";    /* in zephyr/dts/arm/st/h5/stm32h5.dtsi:248 */
			status = "disabled";           /* in zephyr/dts/arm/st/h5/stm32h5.dtsi:249 */
		};

		/* node '/soc/serial@40013800' defined in zephyr/dts/arm/st/h5/stm32h5.dtsi:252 */
		usart1: serial@40013800 {
			compatible = "st,stm32-usart",
			             "st,stm32-uart";  /* in zephyr/dts/arm/st/h5/stm32h5.dtsi:253 */
			reg = < 0x40013800 0x400 >;    /* in zephyr/dts/arm/st/h5/stm32h5.dtsi:254 */
			clocks = < &rcc 0xa4 0x4000 >; /* in zephyr/dts/arm/st/h5/stm32h5.dtsi:255 */
			resets = < &rctl 0xf8e >;      /* in zephyr/dts/arm/st/h5/stm32h5.dtsi:256 */
			interrupts = < 0x3a 0x0 >;     /* in zephyr/dts/arm/st/h5/stm32h5.dtsi:257 */
			status = "disabled";           /* in zephyr/dts/arm/st/h5/stm32h5.dtsi:258 */
		};

		/* node '/soc/serial@40004400' defined in zephyr/dts/arm/st/h5/stm32h5.dtsi:261 */
		usart2: serial@40004400 {
			compatible = "st,stm32-usart",
			             "st,stm32-uart";   /* in zephyr/dts/arm/st/h5/stm32h5.dtsi:262 */
			reg = < 0x40004400 0x400 >;     /* in zephyr/dts/arm/st/h5/stm32h5.dtsi:263 */
			clocks = < &rcc 0x9c 0x20000 >; /* in zephyr/dts/arm/st/h5/stm32h5.dtsi:264 */
			resets = < &rctl 0xe91 >;       /* in zephyr/dts/arm/st/h5/stm32h5.dtsi:265 */
			interrupts = < 0x3b 0x0 >;      /* in zephyr/dts/arm/st/h5/stm32h5.dtsi:266 */
			status = "disabled";            /* in zephyr/dts/arm/st/h5/stm32h5.dtsi:267 */
		};

		/* node '/soc/serial@40004800' defined in zephyr/dts/arm/st/h5/stm32h5.dtsi:270 */
		usart3: serial@40004800 {
			compatible = "st,stm32-usart",
			             "st,stm32-uart";                  /* in zephyr/dts/arm/st/h5/stm32h5.dtsi:271 */
			reg = < 0x40004800 0x400 >;                    /* in zephyr/dts/arm/st/h5/stm32h5.dtsi:272 */
			clocks = < &rcc 0x9c 0x40000 >;                /* in zephyr/dts/arm/st/h5/stm32h5.dtsi:273 */
			resets = < &rctl 0xe92 >;                      /* in zephyr/dts/arm/st/h5/stm32h5.dtsi:274 */
			interrupts = < 0x3c 0x0 >;                     /* in zephyr/dts/arm/st/h5/stm32h5.dtsi:275 */
			pinctrl-0 = < &usart3_tx_pd8 &usart3_rx_pd9 >; /* in zephyr/boards/st/nucleo_h563zi/nucleo_h563zi-common.dtsi:109 */
			pinctrl-names = "default";                     /* in zephyr/boards/st/nucleo_h563zi/nucleo_h563zi-common.dtsi:110 */
			current-speed = < 0x1c200 >;                   /* in zephyr/boards/st/nucleo_h563zi/nucleo_h563zi-common.dtsi:111 */
			status = "okay";                               /* in zephyr/boards/st/nucleo_h563zi/nucleo_h563zi-common.dtsi:112 */
		};

		/* node '/soc/serial@44002400' defined in zephyr/dts/arm/st/h5/stm32h5.dtsi:279 */
		lpuart1: arduino_serial: serial@44002400 {
			compatible = "st,stm32-lpuart",
			             "st,stm32-uart";                    /* in zephyr/dts/arm/st/h5/stm32h5.dtsi:280 */
			reg = < 0x44002400 0x400 >;                      /* in zephyr/dts/arm/st/h5/stm32h5.dtsi:281 */
			clocks = < &rcc 0xa8 0x40 >;                     /* in zephyr/dts/arm/st/h5/stm32h5.dtsi:282 */
			resets = < &rctl 0x1006 >;                       /* in zephyr/dts/arm/st/h5/stm32h5.dtsi:283 */
			interrupts = < 0x3f 0x0 >;                       /* in zephyr/dts/arm/st/h5/stm32h5.dtsi:284 */
			pinctrl-0 = < &lpuart1_tx_pb6 &lpuart1_rx_pb7 >; /* in zephyr/boards/st/nucleo_h563zi/nucleo_h563zi-common.dtsi:102 */
			pinctrl-names = "default";                       /* in zephyr/boards/st/nucleo_h563zi/nucleo_h563zi-common.dtsi:103 */
			current-speed = < 0x1c200 >;                     /* in zephyr/boards/st/nucleo_h563zi/nucleo_h563zi-common.dtsi:104 */
			status = "okay";                                 /* in zephyr/boards/st/nucleo_h563zi/nucleo_h563zi-common.dtsi:105 */
		};

		/* node '/soc/watchdog@40003000' defined in zephyr/dts/arm/st/h5/stm32h5.dtsi:288 */
		iwdg: watchdog@40003000 {
			compatible = "st,stm32-watchdog"; /* in zephyr/dts/arm/st/h5/stm32h5.dtsi:289 */
			reg = < 0x40003000 0x400 >;       /* in zephyr/dts/arm/st/h5/stm32h5.dtsi:290 */
			status = "okay";                  /* in zephyr/boards/st/nucleo_h563zi/nucleo_h563zi-common.dtsi:140 */
		};

		/* node '/soc/watchdog@40002c00' defined in zephyr/dts/arm/st/h5/stm32h5.dtsi:294 */
		wwdg: watchdog@40002c00 {
			compatible = "st,stm32-window-watchdog"; /* in zephyr/dts/arm/st/h5/stm32h5.dtsi:295 */
			reg = < 0x40002c00 0x400 >;              /* in zephyr/dts/arm/st/h5/stm32h5.dtsi:296 */
			clocks = < &rcc 0x9c 0x800 >;            /* in zephyr/dts/arm/st/h5/stm32h5.dtsi:297 */
			interrupts = < 0x0 0x7 >;                /* in zephyr/dts/arm/st/h5/stm32h5.dtsi:298 */
			status = "disabled";                     /* in zephyr/dts/arm/st/h5/stm32h5.dtsi:299 */
		};

		/* node '/soc/dac@42028400' defined in zephyr/dts/arm/st/h5/stm32h5.dtsi:302 */
		dac1: dac@42028400 {
			compatible = "st,stm32-dac";    /* in zephyr/dts/arm/st/h5/stm32h5.dtsi:303 */
			reg = < 0x42028400 0x400 >;     /* in zephyr/dts/arm/st/h5/stm32h5.dtsi:304 */
			clocks = < &rcc 0x8c 0x800 >;   /* in zephyr/dts/arm/st/h5/stm32h5.dtsi:305 */
			#io-channel-cells = < 0x1 >;    /* in zephyr/dts/arm/st/h5/stm32h5.dtsi:307 */
			pinctrl-0 = < &dac1_out2_pa5 >; /* in zephyr/boards/st/nucleo_h563zi/nucleo_h563zi-common.dtsi:153 */
			pinctrl-names = "default";      /* in zephyr/boards/st/nucleo_h563zi/nucleo_h563zi-common.dtsi:154 */
			status = "okay";                /* in zephyr/boards/st/nucleo_h563zi/nucleo_h563zi-common.dtsi:155 */
		};

		/* node '/soc/adc@42028000' defined in zephyr/dts/arm/st/h5/stm32h5.dtsi:310 */
		adc1: adc@42028000 {
			compatible = "st,stm32-adc";                                /* in zephyr/dts/arm/st/h5/stm32h5.dtsi:311 */
			reg = < 0x42028000 0x400 >;                                 /* in zephyr/dts/arm/st/h5/stm32h5.dtsi:312 */
			interrupts = < 0x25 0x0 >;                                  /* in zephyr/dts/arm/st/h5/stm32h5.dtsi:314 */
			vref-mv = < 0xce4 >;                                        /* in zephyr/dts/arm/st/h5/stm32h5.dtsi:316 */
			#io-channel-cells = < 0x1 >;                                /* in zephyr/dts/arm/st/h5/stm32h5.dtsi:317 */
			resolutions = < 0x60630c 0x51630c 0x42630c 0x33630c >;      /* in zephyr/dts/arm/st/h5/stm32h5.dtsi:318 */
			sampling-times = < 0x3 0x7 0xd 0x19 0x30 0x5d 0xf8 0x281 >; /* in zephyr/dts/arm/st/h5/stm32h5.dtsi:322 */
			st,adc-sequencer = "FULLY_CONFIGURABLE";                    /* in zephyr/dts/arm/st/h5/stm32h5.dtsi:323 */
			st,adc-oversampler = "OVERSAMPLER_MINIMAL";                 /* in zephyr/dts/arm/st/h5/stm32h5.dtsi:324 */
			clocks = < &rcc 0x8c 0x400 >,
			         < &rcc 0x8 0x1c000e8 >;                            /* in zephyr/boards/st/nucleo_h563zi/nucleo_h563zi-common.dtsi:159 */
			pinctrl-0 = < &adc1_inp3_pa6 &adc1_inp15_pa3 >;             /* in zephyr/boards/st/nucleo_h563zi/nucleo_h563zi-common.dtsi:161 */
			pinctrl-names = "default";                                  /* in zephyr/boards/st/nucleo_h563zi/nucleo_h563zi-common.dtsi:162 */
			st,adc-clock-source = "ASYNC";                              /* in zephyr/boards/st/nucleo_h563zi/nucleo_h563zi-common.dtsi:163 */
			st,adc-prescaler = < 0x6 >;                                 /* in zephyr/boards/st/nucleo_h563zi/nucleo_h563zi-common.dtsi:164 */
			status = "okay";                                            /* in zephyr/boards/st/nucleo_h563zi/nucleo_h563zi-common.dtsi:165 */
			phandle = < 0x27 >;                                         /* in zephyr/dts/arm/st/h5/stm32h5.dtsi:691 */
		};

		/* node '/soc/rtc@44007800' defined in zephyr/dts/arm/st/h5/stm32h5.dtsi:327 */
		rtc: rtc@44007800 {
			compatible = "st,stm32-rtc";     /* in zephyr/dts/arm/st/h5/stm32h5.dtsi:328 */
			reg = < 0x44007800 0x400 >;      /* in zephyr/dts/arm/st/h5/stm32h5.dtsi:329 */
			interrupts = < 0x2 0x0 >;        /* in zephyr/dts/arm/st/h5/stm32h5.dtsi:330 */
			prescaler = < 0x8000 >;          /* in zephyr/dts/arm/st/h5/stm32h5.dtsi:332 */
			alarms-count = < 0x2 >;          /* in zephyr/dts/arm/st/h5/stm32h5.dtsi:333 */
			alrm-exti-line = < 0x11 >;       /* in zephyr/dts/arm/st/h5/stm32h5.dtsi:334 */
			clocks = < &rcc 0xa8 0x200000 >,
			         < &rcc 0x2 0x8c800f0 >; /* in zephyr/boards/st/nucleo_h563zi/nucleo_h563zi-common.dtsi:134 */
			status = "okay";                 /* in zephyr/boards/st/nucleo_h563zi/nucleo_h563zi-common.dtsi:136 */
		};

		/* node '/soc/timers@40012c00' defined in zephyr/dts/arm/st/h5/stm32h5.dtsi:338 */
		timers1: timers@40012c00 {
			compatible = "st,stm32-timers"; /* in zephyr/dts/arm/st/h5/stm32h5.dtsi:339 */
			reg = < 0x40012c00 0x400 >;     /* in zephyr/dts/arm/st/h5/stm32h5.dtsi:340 */
			clocks = < &rcc 0xa4 0x800 >;   /* in zephyr/dts/arm/st/h5/stm32h5.dtsi:341 */
			resets = < &rctl 0xf8b >;       /* in zephyr/dts/arm/st/h5/stm32h5.dtsi:342 */
			interrupts = < 0x29 0x0 >,
			             < 0x2a 0x0 >,
			             < 0x2b 0x0 >,
			             < 0x2c 0x0 >;      /* in zephyr/dts/arm/st/h5/stm32h5.dtsi:343 */
			interrupt-names = "brk",
			                  "up",
			                  "trgcom",
			                  "cc";         /* in zephyr/dts/arm/st/h5/stm32h5.dtsi:344 */
			status = "disabled";            /* in zephyr/dts/arm/st/h5/stm32h5.dtsi:345 */

			/* node '/soc/timers@40012c00/pwm' defined in zephyr/dts/arm/st/h5/stm32h5.dtsi:347 */
			pwm {
				compatible = "st,stm32-pwm"; /* in zephyr/dts/arm/st/h5/stm32h5.dtsi:348 */
				status = "disabled";         /* in zephyr/dts/arm/st/h5/stm32h5.dtsi:349 */
				#pwm-cells = < 0x3 >;        /* in zephyr/dts/arm/st/h5/stm32h5.dtsi:350 */
			};
		};

		/* node '/soc/timers@40000000' defined in zephyr/dts/arm/st/h5/stm32h5.dtsi:354 */
		timers2: timers@40000000 {
			compatible = "st,stm32-timers"; /* in zephyr/dts/arm/st/h5/stm32h5.dtsi:355 */
			reg = < 0x40000000 0x400 >;     /* in zephyr/dts/arm/st/h5/stm32h5.dtsi:356 */
			clocks = < &rcc 0x9c 0x1 >;     /* in zephyr/dts/arm/st/h5/stm32h5.dtsi:357 */
			resets = < &rctl 0xe80 >;       /* in zephyr/dts/arm/st/h5/stm32h5.dtsi:358 */
			interrupts = < 0x2d 0x0 >;      /* in zephyr/dts/arm/st/h5/stm32h5.dtsi:359 */
			interrupt-names = "global";     /* in zephyr/dts/arm/st/h5/stm32h5.dtsi:360 */
			status = "disabled";            /* in zephyr/dts/arm/st/h5/stm32h5.dtsi:361 */

			/* node '/soc/timers@40000000/pwm' defined in zephyr/dts/arm/st/h5/stm32h5.dtsi:363 */
			pwm {
				compatible = "st,stm32-pwm"; /* in zephyr/dts/arm/st/h5/stm32h5.dtsi:364 */
				status = "disabled";         /* in zephyr/dts/arm/st/h5/stm32h5.dtsi:365 */
				#pwm-cells = < 0x3 >;        /* in zephyr/dts/arm/st/h5/stm32h5.dtsi:366 */
			};

			/* node '/soc/timers@40000000/counter' defined in zephyr/dts/arm/st/h5/stm32h5.dtsi:369 */
			counter {
				compatible = "st,stm32-counter"; /* in zephyr/dts/arm/st/h5/stm32h5.dtsi:370 */
				status = "disabled";             /* in zephyr/dts/arm/st/h5/stm32h5.dtsi:371 */
			};
		};

		/* node '/soc/timers@40000400' defined in zephyr/dts/arm/st/h5/stm32h5.dtsi:375 */
		timers3: timers@40000400 {
			compatible = "st,stm32-timers"; /* in zephyr/dts/arm/st/h5/stm32h5.dtsi:376 */
			reg = < 0x40000400 0x400 >;     /* in zephyr/dts/arm/st/h5/stm32h5.dtsi:377 */
			clocks = < &rcc 0x9c 0x2 >;     /* in zephyr/dts/arm/st/h5/stm32h5.dtsi:378 */
			resets = < &rctl 0xe81 >;       /* in zephyr/dts/arm/st/h5/stm32h5.dtsi:379 */
			interrupts = < 0x2e 0x0 >;      /* in zephyr/dts/arm/st/h5/stm32h5.dtsi:380 */
			interrupt-names = "global";     /* in zephyr/dts/arm/st/h5/stm32h5.dtsi:381 */
			st,prescaler = < 0x2710 >;      /* in zephyr/boards/st/nucleo_h563zi/nucleo_h563zi-common.dtsi:123 */
			status = "okay";                /* in zephyr/boards/st/nucleo_h563zi/nucleo_h563zi-common.dtsi:124 */

			/* node '/soc/timers@40000400/pwm' defined in zephyr/dts/arm/st/h5/stm32h5.dtsi:384 */
			pwm3: pwm {
				compatible = "st,stm32-pwm";   /* in zephyr/dts/arm/st/h5/stm32h5.dtsi:385 */
				#pwm-cells = < 0x3 >;          /* in zephyr/dts/arm/st/h5/stm32h5.dtsi:387 */
				status = "okay";               /* in zephyr/boards/st/nucleo_h563zi/nucleo_h563zi-common.dtsi:127 */
				pinctrl-0 = < &tim3_ch3_pb0 >; /* in zephyr/boards/st/nucleo_h563zi/nucleo_h563zi-common.dtsi:128 */
				pinctrl-names = "default";     /* in zephyr/boards/st/nucleo_h563zi/nucleo_h563zi-common.dtsi:129 */
				phandle = < 0x33 >;            /* in zephyr/boards/st/nucleo_h563zi/nucleo_h563zi-common.dtsi:49 */
			};

			/* node '/soc/timers@40000400/counter' defined in zephyr/dts/arm/st/h5/stm32h5.dtsi:390 */
			counter {
				compatible = "st,stm32-counter"; /* in zephyr/dts/arm/st/h5/stm32h5.dtsi:391 */
				status = "disabled";             /* in zephyr/dts/arm/st/h5/stm32h5.dtsi:392 */
			};
		};

		/* node '/soc/timers@40001000' defined in zephyr/dts/arm/st/h5/stm32h5.dtsi:396 */
		timers6: timers@40001000 {
			compatible = "st,stm32-timers"; /* in zephyr/dts/arm/st/h5/stm32h5.dtsi:397 */
			reg = < 0x40001000 0x400 >;     /* in zephyr/dts/arm/st/h5/stm32h5.dtsi:398 */
			clocks = < &rcc 0x9c 0x10 >;    /* in zephyr/dts/arm/st/h5/stm32h5.dtsi:399 */
			resets = < &rctl 0xe84 >;       /* in zephyr/dts/arm/st/h5/stm32h5.dtsi:400 */
			interrupts = < 0x31 0x0 >;      /* in zephyr/dts/arm/st/h5/stm32h5.dtsi:401 */
			interrupt-names = "global";     /* in zephyr/dts/arm/st/h5/stm32h5.dtsi:402 */
			status = "disabled";            /* in zephyr/dts/arm/st/h5/stm32h5.dtsi:403 */

			/* node '/soc/timers@40001000/pwm' defined in zephyr/dts/arm/st/h5/stm32h5.dtsi:405 */
			pwm {
				compatible = "st,stm32-pwm"; /* in zephyr/dts/arm/st/h5/stm32h5.dtsi:406 */
				status = "disabled";         /* in zephyr/dts/arm/st/h5/stm32h5.dtsi:407 */
				#pwm-cells = < 0x3 >;        /* in zephyr/dts/arm/st/h5/stm32h5.dtsi:408 */
			};

			/* node '/soc/timers@40001000/counter' defined in zephyr/dts/arm/st/h5/stm32h5.dtsi:411 */
			counter {
				compatible = "st,stm32-counter"; /* in zephyr/dts/arm/st/h5/stm32h5.dtsi:412 */
				status = "disabled";             /* in zephyr/dts/arm/st/h5/stm32h5.dtsi:413 */
			};
		};

		/* node '/soc/timers@40001400' defined in zephyr/dts/arm/st/h5/stm32h5.dtsi:417 */
		timers7: timers@40001400 {
			compatible = "st,stm32-timers"; /* in zephyr/dts/arm/st/h5/stm32h5.dtsi:418 */
			reg = < 0x40001400 0x400 >;     /* in zephyr/dts/arm/st/h5/stm32h5.dtsi:419 */
			clocks = < &rcc 0x9c 0x20 >;    /* in zephyr/dts/arm/st/h5/stm32h5.dtsi:420 */
			resets = < &rctl 0xe85 >;       /* in zephyr/dts/arm/st/h5/stm32h5.dtsi:421 */
			interrupts = < 0x32 0x0 >;      /* in zephyr/dts/arm/st/h5/stm32h5.dtsi:422 */
			interrupt-names = "global";     /* in zephyr/dts/arm/st/h5/stm32h5.dtsi:423 */
			status = "disabled";            /* in zephyr/dts/arm/st/h5/stm32h5.dtsi:424 */

			/* node '/soc/timers@40001400/pwm' defined in zephyr/dts/arm/st/h5/stm32h5.dtsi:426 */
			pwm {
				compatible = "st,stm32-pwm"; /* in zephyr/dts/arm/st/h5/stm32h5.dtsi:427 */
				status = "disabled";         /* in zephyr/dts/arm/st/h5/stm32h5.dtsi:428 */
				#pwm-cells = < 0x3 >;        /* in zephyr/dts/arm/st/h5/stm32h5.dtsi:429 */
			};

			/* node '/soc/timers@40001400/counter' defined in zephyr/dts/arm/st/h5/stm32h5.dtsi:432 */
			counter {
				compatible = "st,stm32-counter"; /* in zephyr/dts/arm/st/h5/stm32h5.dtsi:433 */
				status = "disabled";             /* in zephyr/dts/arm/st/h5/stm32h5.dtsi:434 */
			};
		};

		/* node '/soc/i2c@40005400' defined in zephyr/dts/arm/st/h5/stm32h5.dtsi:438 */
		i2c1: arduino_i2c: i2c@40005400 {
			compatible = "st,stm32-i2c-v2";              /* in zephyr/dts/arm/st/h5/stm32h5.dtsi:439 */
			clock-frequency = < 0x186a0 >;               /* in zephyr/dts/arm/st/h5/stm32h5.dtsi:440 */
			#address-cells = < 0x1 >;                    /* in zephyr/dts/arm/st/h5/stm32h5.dtsi:441 */
			#size-cells = < 0x0 >;                       /* in zephyr/dts/arm/st/h5/stm32h5.dtsi:442 */
			reg = < 0x40005400 0x400 >;                  /* in zephyr/dts/arm/st/h5/stm32h5.dtsi:443 */
			clocks = < &rcc 0x9c 0x200000 >;             /* in zephyr/dts/arm/st/h5/stm32h5.dtsi:444 */
			interrupts = < 0x33 0x0 >,
			             < 0x34 0x0 >;                   /* in zephyr/dts/arm/st/h5/stm32h5.dtsi:445 */
			interrupt-names = "event",
			                  "error";                   /* in zephyr/dts/arm/st/h5/stm32h5.dtsi:446 */
			pinctrl-0 = < &i2c1_scl_pb8 &i2c1_sda_pb9 >; /* in zephyr/boards/st/nucleo_h563zi/nucleo_h563zi-common.dtsi:80 */
			pinctrl-names = "default";                   /* in zephyr/boards/st/nucleo_h563zi/nucleo_h563zi-common.dtsi:81 */
			status = "okay";                             /* in zephyr/boards/st/nucleo_h563zi/nucleo_h563zi-common.dtsi:82 */
			phandle = < 0x28 >;                          /* in zephyr/dts/arm/st/h5/stm32h5.dtsi:719 */
		};

		/* node '/soc/i2c@40005800' defined in zephyr/dts/arm/st/h5/stm32h5.dtsi:450 */
		i2c2: i2c@40005800 {
			compatible = "st,stm32-i2c-v2";  /* in zephyr/dts/arm/st/h5/stm32h5.dtsi:451 */
			clock-frequency = < 0x186a0 >;   /* in zephyr/dts/arm/st/h5/stm32h5.dtsi:452 */
			#address-cells = < 0x1 >;        /* in zephyr/dts/arm/st/h5/stm32h5.dtsi:453 */
			#size-cells = < 0x0 >;           /* in zephyr/dts/arm/st/h5/stm32h5.dtsi:454 */
			reg = < 0x40005800 0x400 >;      /* in zephyr/dts/arm/st/h5/stm32h5.dtsi:455 */
			clocks = < &rcc 0x9c 0x400000 >; /* in zephyr/dts/arm/st/h5/stm32h5.dtsi:456 */
			interrupts = < 0x35 0x0 >,
			             < 0x36 0x0 >;       /* in zephyr/dts/arm/st/h5/stm32h5.dtsi:457 */
			interrupt-names = "event",
			                  "error";       /* in zephyr/dts/arm/st/h5/stm32h5.dtsi:458 */
			status = "disabled";             /* in zephyr/dts/arm/st/h5/stm32h5.dtsi:459 */
			phandle = < 0x29 >;              /* in zephyr/dts/arm/st/h5/stm32h5.dtsi:727 */
		};

		/* node '/soc/i3c@40005c00' defined in zephyr/dts/arm/st/h5/stm32h5.dtsi:462 */
		i3c1: i3c@40005c00 {
			compatible = "st,stm32-i3c";                   /* in zephyr/dts/arm/st/h5/stm32h5.dtsi:463 */
			reg = < 0x40005c00 0x400 >;                    /* in zephyr/dts/arm/st/h5/stm32h5.dtsi:464 */
			interrupts = < 0x7b 0x0 >,
			             < 0x7c 0x0 >;                     /* in zephyr/dts/arm/st/h5/stm32h5.dtsi:465 */
			interrupt-names = "event",
			                  "error";                     /* in zephyr/dts/arm/st/h5/stm32h5.dtsi:466 */
			#address-cells = < 0x3 >;                      /* in zephyr/dts/arm/st/h5/stm32h5.dtsi:467 */
			#size-cells = < 0x0 >;                         /* in zephyr/dts/arm/st/h5/stm32h5.dtsi:468 */
			clocks = < &rcc 0x9c 0x800000 >;               /* in zephyr/dts/arm/st/h5/stm32h5.dtsi:469 */
			resets = < &rctl 0xe97 >;                      /* in zephyr/dts/arm/st/h5/stm32h5.dtsi:470 */
			zephyr,pm-device-runtime-auto;                 /* in zephyr/dts/arm/st/h5/stm32h5.dtsi:471 */
			pinctrl-0 = < &i3c1_scl_pd12 &i3c1_sda_pd13 >; /* in zephyr/boards/st/nucleo_h563zi/nucleo_h563zi-common.dtsi:86 */
			pinctrl-names = "default";                     /* in zephyr/boards/st/nucleo_h563zi/nucleo_h563zi-common.dtsi:87 */
			i3c-scl-hz = < 0xbebc20 >;                     /* in zephyr/boards/st/nucleo_h563zi/nucleo_h563zi-common.dtsi:88 */
			status = "okay";                               /* in zephyr/boards/st/nucleo_h563zi/nucleo_h563zi-common.dtsi:89 */
		};

		/* node '/soc/i3c@44003000' defined in zephyr/dts/arm/st/h5/stm32h5.dtsi:475 */
		i3c2: i3c@44003000 {
			compatible = "st,stm32-i3c";   /* in zephyr/dts/arm/st/h5/stm32h5.dtsi:476 */
			reg = < 0x44003000 0x400 >;    /* in zephyr/dts/arm/st/h5/stm32h5.dtsi:477 */
			interrupts = < 0x83 0x0 >,
			             < 0x84 0x0 >;     /* in zephyr/dts/arm/st/h5/stm32h5.dtsi:478 */
			interrupt-names = "event",
			                  "error";     /* in zephyr/dts/arm/st/h5/stm32h5.dtsi:479 */
			#address-cells = < 0x3 >;      /* in zephyr/dts/arm/st/h5/stm32h5.dtsi:480 */
			#size-cells = < 0x0 >;         /* in zephyr/dts/arm/st/h5/stm32h5.dtsi:481 */
			clocks = < &rcc 0xa8 0x200 >;  /* in zephyr/dts/arm/st/h5/stm32h5.dtsi:482 */
			resets = < &rctl 0x1009 >;     /* in zephyr/dts/arm/st/h5/stm32h5.dtsi:483 */
			zephyr,pm-device-runtime-auto; /* in zephyr/dts/arm/st/h5/stm32h5.dtsi:484 */
			status = "disabled";           /* in zephyr/dts/arm/st/h5/stm32h5.dtsi:485 */
		};

		/* node '/soc/spi@40013000' defined in zephyr/dts/arm/st/h5/stm32h5.dtsi:488 */
		spi1: arduino_spi: spi@40013000 {
			compatible = "st,stm32h7-spi",
			             "st,stm32-spi-fifo",
			             "st,stm32-spi";                                 /* in zephyr/dts/arm/st/h5/stm32h5.dtsi:489 */
			#address-cells = < 0x1 >;                                    /* in zephyr/dts/arm/st/h5/stm32h5.dtsi:490 */
			#size-cells = < 0x0 >;                                       /* in zephyr/dts/arm/st/h5/stm32h5.dtsi:491 */
			reg = < 0x40013000 0x400 >;                                  /* in zephyr/dts/arm/st/h5/stm32h5.dtsi:492 */
			interrupts = < 0x37 0x5 >;                                   /* in zephyr/dts/arm/st/h5/stm32h5.dtsi:493 */
			clocks = < &rcc 0xa4 0x1000 >,
			         < &rcc 0xd 0x1c000e0 >;                             /* in zephyr/dts/arm/st/h5/stm32h5.dtsi:494 */
			pinctrl-0 = < &spi1_sck_pa5 &spi1_miso_pg9 &spi1_mosi_pb5 >; /* in zephyr/boards/st/nucleo_h563zi/nucleo_h563zi-common.dtsi:116 */
			pinctrl-names = "default";                                   /* in zephyr/boards/st/nucleo_h563zi/nucleo_h563zi-common.dtsi:117 */
			cs-gpios = < &gpiod 0xe 0x11 >;                              /* in zephyr/boards/st/nucleo_h563zi/nucleo_h563zi-common.dtsi:118 */
			status = "okay";                                             /* in zephyr/boards/st/nucleo_h563zi/nucleo_h563zi-common.dtsi:119 */
		};

		/* node '/soc/spi@40003800' defined in zephyr/dts/arm/st/h5/stm32h5.dtsi:499 */
		spi2: spi@40003800 {
			compatible = "st,stm32h7-spi",
			             "st,stm32-spi-fifo",
			             "st,stm32-spi";      /* in zephyr/dts/arm/st/h5/stm32h5.dtsi:500 */
			#address-cells = < 0x1 >;         /* in zephyr/dts/arm/st/h5/stm32h5.dtsi:501 */
			#size-cells = < 0x0 >;            /* in zephyr/dts/arm/st/h5/stm32h5.dtsi:502 */
			reg = < 0x40003800 0x400 >;       /* in zephyr/dts/arm/st/h5/stm32h5.dtsi:503 */
			interrupts = < 0x38 0x5 >;        /* in zephyr/dts/arm/st/h5/stm32h5.dtsi:504 */
			clocks = < &rcc 0x9c 0x4000 >,
			         < &rcc 0xd 0x1c300e0 >;  /* in zephyr/dts/arm/st/h5/stm32h5.dtsi:505 */
			status = "disabled";              /* in zephyr/dts/arm/st/h5/stm32h5.dtsi:507 */
		};

		/* node '/soc/spi@40003c00' defined in zephyr/dts/arm/st/h5/stm32h5.dtsi:510 */
		spi3: spi@40003c00 {
			compatible = "st,stm32h7-spi",
			             "st,stm32-spi-fifo",
			             "st,stm32-spi";      /* in zephyr/dts/arm/st/h5/stm32h5.dtsi:511 */
			#address-cells = < 0x1 >;         /* in zephyr/dts/arm/st/h5/stm32h5.dtsi:512 */
			#size-cells = < 0x0 >;            /* in zephyr/dts/arm/st/h5/stm32h5.dtsi:513 */
			reg = < 0x40003c00 0x400 >;       /* in zephyr/dts/arm/st/h5/stm32h5.dtsi:514 */
			interrupts = < 0x39 0x5 >;        /* in zephyr/dts/arm/st/h5/stm32h5.dtsi:515 */
			clocks = < &rcc 0x9c 0x8000 >,
			         < &rcc 0xd 0x1c600e0 >;  /* in zephyr/dts/arm/st/h5/stm32h5.dtsi:516 */
			status = "disabled";              /* in zephyr/dts/arm/st/h5/stm32h5.dtsi:518 */
		};

		/* node '/soc/can@4000a400' defined in zephyr/dts/arm/st/h5/stm32h5.dtsi:521 */
		fdcan1: can@4000a400 {
			compatible = "st,stm32-fdcan";                         /* in zephyr/dts/arm/st/h5/stm32h5.dtsi:522 */
			reg = < 0x4000a400 0x400 >,
			      < 0x4000ac00 0x350 >;                            /* in zephyr/dts/arm/st/h5/stm32h5.dtsi:523 */
			reg-names = "m_can",
			            "message_ram";                             /* in zephyr/dts/arm/st/h5/stm32h5.dtsi:524 */
			interrupts = < 0x27 0x0 >,
			             < 0x28 0x0 >;                             /* in zephyr/dts/arm/st/h5/stm32h5.dtsi:525 */
			interrupt-names = "int0",
			                  "int1";                              /* in zephyr/dts/arm/st/h5/stm32h5.dtsi:526 */
			bosch,mram-cfg = < 0x0 0x1c 0x8 0x3 0x3 0x0 0x3 0x3 >; /* in zephyr/dts/arm/st/h5/stm32h5.dtsi:528 */
			pinctrl-0 = < &fdcan1_rx_pd0 &fdcan1_tx_pd1 >;         /* in zephyr/boards/st/nucleo_h563zi/nucleo_h563zi-common.dtsi:169 */
			pinctrl-names = "default";                             /* in zephyr/boards/st/nucleo_h563zi/nucleo_h563zi-common.dtsi:170 */
			clocks = < &rcc 0xa0 0x200 >,
			         < &rcc 0xd 0x8c800e8 >;                       /* in zephyr/boards/st/nucleo_h563zi/nucleo_h563zi-common.dtsi:171 */
			clk-divider = < 0x2 >;                                 /* in zephyr/boards/st/nucleo_h563zi/nucleo_h563zi-common.dtsi:173 */
			status = "okay";                                       /* in zephyr/boards/st/nucleo_h563zi/nucleo_h563zi-common.dtsi:174 */
		};

		/* node '/soc/rng@420c0800' defined in zephyr/dts/arm/st/h5/stm32h5.dtsi:532 */
		rng: rng@420c0800 {
			compatible = "st,stm32-rng";     /* in zephyr/dts/arm/st/h5/stm32h5.dtsi:533 */
			reg = < 0x420c0800 0x400 >;      /* in zephyr/dts/arm/st/h5/stm32h5.dtsi:534 */
			clocks = < &rcc 0x8c 0x40000 >;  /* in zephyr/dts/arm/st/h5/stm32h5.dtsi:535 */
			interrupts = < 0x72 0x0 >;       /* in zephyr/dts/arm/st/h5/stm32h5.dtsi:536 */
			nist-config = < 0xf00d00 >;      /* in zephyr/dts/arm/st/h5/stm32h5.dtsi:537 */
			health-test-config = < 0xaac7 >; /* in zephyr/dts/arm/st/h5/stm32h5.dtsi:538 */
			status = "okay";                 /* in zephyr/boards/st/nucleo_h563zi/nucleo_h563zi.dts:39 */
		};

		/* node '/soc/ethernet@40028000' defined in zephyr/dts/arm/st/h5/stm32h5.dtsi:542 */
		ethernet@40028000 {
			reg = < 0x40028000 0x8000 >;                 /* in zephyr/dts/arm/st/h5/stm32h5.dtsi:543 */
			compatible = "st,stm32-ethernet-controller"; /* in zephyr/dts/arm/st/h5/stm32h5.dtsi:544 */
			clock-names = "stm-eth";                     /* in zephyr/dts/arm/st/h5/stm32h5.dtsi:545 */
			clocks = < &rcc 0x88 0x80000 >;              /* in zephyr/dts/arm/st/h5/stm32h5.dtsi:546 */

			/* node '/soc/ethernet@40028000/ethernet' defined in zephyr/dts/arm/st/h5/stm32h5.dtsi:548 */
			mac: ethernet {
				compatible = "st,stm32h7-ethernet",
				             "st,stm32-ethernet";                                                                         /* in zephyr/dts/arm/st/h5/stm32h5.dtsi:549 */
				interrupts = < 0x6a 0x0 >;                                                                                /* in zephyr/dts/arm/st/h5/stm32h5.dtsi:550 */
				clock-names = "mac-clk-tx",
				              "mac-clk-rx";                                                                               /* in zephyr/dts/arm/st/h5/stm32h5.dtsi:551 */
				clocks = < &rcc 0x88 0x100000 >,
				         < &rcc 0x88 0x200000 >;                                                                          /* in zephyr/dts/arm/st/h5/stm32h5.dtsi:552 */
				status = "okay";                                                                                          /* in zephyr/boards/st/nucleo_h563zi/nucleo_h563zi.dts:43 */
				pinctrl-0 = < &eth_rxd0_pc4 &eth_rxd1_pc5 &eth_ref_clk_pa1 &eth_crs_dv_pa7 &eth_tx_en_pg11 &eth_txd0_pg13
				              &eth_txd1_pb15 >;                                                                           /* in zephyr/boards/st/nucleo_h563zi/nucleo_h563zi.dts:44 */
				pinctrl-names = "default";                                                                                /* in zephyr/boards/st/nucleo_h563zi/nucleo_h563zi.dts:51 */
				phy-connection-type = "rmii";                                                                             /* in zephyr/boards/st/nucleo_h563zi/nucleo_h563zi.dts:52 */
				phy-handle = < &eth_phy >;                                                                                /* in zephyr/boards/st/nucleo_h563zi/nucleo_h563zi.dts:53 */
			};

			/* node '/soc/ethernet@40028000/mdio' defined in zephyr/dts/arm/st/h5/stm32h5.dtsi:557 */
			mdio: mdio {
				compatible = "st,stm32-mdio";               /* in zephyr/dts/arm/st/h5/stm32h5.dtsi:558 */
				#address-cells = < 0x1 >;                   /* in zephyr/dts/arm/st/h5/stm32h5.dtsi:559 */
				#size-cells = < 0x0 >;                      /* in zephyr/dts/arm/st/h5/stm32h5.dtsi:560 */
				status = "okay";                            /* in zephyr/boards/st/nucleo_h563zi/nucleo_h563zi.dts:57 */
				pinctrl-0 = < &eth_mdio_pa2 &eth_mdc_pc1 >; /* in zephyr/boards/st/nucleo_h563zi/nucleo_h563zi.dts:58 */
				pinctrl-names = "default";                  /* in zephyr/boards/st/nucleo_h563zi/nucleo_h563zi.dts:59 */

				/* node '/soc/ethernet@40028000/mdio/ethernet-phy@0' defined in zephyr/boards/st/nucleo_h563zi/nucleo_h563zi.dts:61 */
				eth_phy: ethernet-phy@0 {
					compatible = "ethernet-phy"; /* in zephyr/boards/st/nucleo_h563zi/nucleo_h563zi.dts:62 */
					reg = < 0x0 >;               /* in zephyr/boards/st/nucleo_h563zi/nucleo_h563zi.dts:63 */
					phandle = < 0x1e >;          /* in zephyr/boards/st/nucleo_h563zi/nucleo_h563zi.dts:53 */
				};
			};
		};

		/* node '/soc/dma@40020000' defined in zephyr/dts/arm/st/h5/stm32h5.dtsi:565 */
		gpdma1: dma@40020000 {
			compatible = "st,stm32u5-dma";                                                            /* in zephyr/dts/arm/st/h5/stm32h5.dtsi:566 */
			#dma-cells = < 0x3 >;                                                                     /* in zephyr/dts/arm/st/h5/stm32h5.dtsi:567 */
			reg = < 0x40020000 0x1000 >;                                                              /* in zephyr/dts/arm/st/h5/stm32h5.dtsi:568 */
			interrupts = < 0x1b 0x0 0x1c 0x0 0x1d 0x0 0x1e 0x0 0x1f 0x0 0x20 0x0 0x21 0x0 0x22 0x0 >; /* in zephyr/dts/arm/st/h5/stm32h5.dtsi:569 */
			clocks = < &rcc 0x88 0x1 >;                                                               /* in zephyr/dts/arm/st/h5/stm32h5.dtsi:570 */
			dma-channels = < 0x8 >;                                                                   /* in zephyr/dts/arm/st/h5/stm32h5.dtsi:571 */
			dma-requests = < 0x8c >;                                                                  /* in zephyr/dts/arm/st/h5/stm32h5.dtsi:572 */
			dma-offset = < 0x0 >;                                                                     /* in zephyr/dts/arm/st/h5/stm32h5.dtsi:573 */
			status = "okay";                                                                          /* in zephyr/boards/st/nucleo_h563zi/nucleo_h563zi-common.dtsi:144 */
			phandle = < 0x21 >;                                                                       /* in zephyr/dts/arm/st/h5/stm32h5.dtsi:596 */
		};

		/* node '/soc/dma@40021000' defined in zephyr/dts/arm/st/h5/stm32h5.dtsi:577 */
		gpdma2: dma@40021000 {
			compatible = "st,stm32u5-dma";                                                            /* in zephyr/dts/arm/st/h5/stm32h5.dtsi:578 */
			#dma-cells = < 0x3 >;                                                                     /* in zephyr/dts/arm/st/h5/stm32h5.dtsi:579 */
			reg = < 0x40021000 0x1000 >;                                                              /* in zephyr/dts/arm/st/h5/stm32h5.dtsi:580 */
			interrupts = < 0x5a 0x0 0x5b 0x0 0x5c 0x0 0x5d 0x0 0x5e 0x0 0x5f 0x0 0x60 0x0 0x61 0x0 >; /* in zephyr/dts/arm/st/h5/stm32h5.dtsi:581 */
			clocks = < &rcc 0x88 0x2 >;                                                               /* in zephyr/dts/arm/st/h5/stm32h5.dtsi:582 */
			dma-channels = < 0x8 >;                                                                   /* in zephyr/dts/arm/st/h5/stm32h5.dtsi:583 */
			dma-requests = < 0x8c >;                                                                  /* in zephyr/dts/arm/st/h5/stm32h5.dtsi:584 */
			dma-offset = < 0x8 >;                                                                     /* in zephyr/dts/arm/st/h5/stm32h5.dtsi:585 */
			status = "okay";                                                                          /* in zephyr/boards/st/nucleo_h563zi/nucleo_h563zi-common.dtsi:148 */
		};

		/* node '/soc/i2s@40013000' defined in zephyr/dts/arm/st/h5/stm32h5.dtsi:589 */
		i2s1: i2s@40013000 {
			compatible = "st,stm32h7-i2s",
			             "st,stm32-i2s";                                /* in zephyr/dts/arm/st/h5/stm32h5.dtsi:590 */
			#address-cells = < 0x1 >;                                   /* in zephyr/dts/arm/st/h5/stm32h5.dtsi:591 */
			#size-cells = < 0x0 >;                                      /* in zephyr/dts/arm/st/h5/stm32h5.dtsi:592 */
			reg = < 0x40013000 0x400 >;                                 /* in zephyr/dts/arm/st/h5/stm32h5.dtsi:593 */
			clocks = < &rcc 0xa4 0x1000 >,
			         < &rcc 0xd 0x1c000e0 >;                            /* in zephyr/dts/arm/st/h5/stm32h5.dtsi:594 */
			dmas = < &gpdma1 0x0 0x7 0x22c40 &gpdma1 0x1 0x6 0x22c80 >; /* in zephyr/dts/arm/st/h5/stm32h5.dtsi:596 */
			dma-names = "tx",
			            "rx";                                           /* in zephyr/dts/arm/st/h5/stm32h5.dtsi:600 */
			interrupts = < 0x37 0x3 >;                                  /* in zephyr/dts/arm/st/h5/stm32h5.dtsi:601 */
			status = "disabled";                                        /* in zephyr/dts/arm/st/h5/stm32h5.dtsi:602 */
		};

		/* node '/soc/i2s@40003800' defined in zephyr/dts/arm/st/h5/stm32h5.dtsi:605 */
		i2s2: i2s@40003800 {
			compatible = "st,stm32h7-i2s",
			             "st,stm32-i2s";                                /* in zephyr/dts/arm/st/h5/stm32h5.dtsi:606 */
			#address-cells = < 0x1 >;                                   /* in zephyr/dts/arm/st/h5/stm32h5.dtsi:607 */
			#size-cells = < 0x0 >;                                      /* in zephyr/dts/arm/st/h5/stm32h5.dtsi:608 */
			reg = < 0x40003800 0x400 >;                                 /* in zephyr/dts/arm/st/h5/stm32h5.dtsi:609 */
			clocks = < &rcc 0x9c 0x4000 >,
			         < &rcc 0xd 0x1c300e0 >;                            /* in zephyr/dts/arm/st/h5/stm32h5.dtsi:610 */
			dmas = < &gpdma1 0x2 0x9 0x22c40 &gpdma1 0x3 0x8 0x22c80 >; /* in zephyr/dts/arm/st/h5/stm32h5.dtsi:612 */
			dma-names = "tx",
			            "rx";                                           /* in zephyr/dts/arm/st/h5/stm32h5.dtsi:616 */
			interrupts = < 0x38 0x3 >;                                  /* in zephyr/dts/arm/st/h5/stm32h5.dtsi:617 */
			status = "disabled";                                        /* in zephyr/dts/arm/st/h5/stm32h5.dtsi:618 */
		};

		/* node '/soc/i2s@40003c00' defined in zephyr/dts/arm/st/h5/stm32h5.dtsi:621 */
		i2s3: i2s@40003c00 {
			compatible = "st,stm32h7-i2s",
			             "st,stm32-i2s";                                /* in zephyr/dts/arm/st/h5/stm32h5.dtsi:622 */
			#address-cells = < 0x1 >;                                   /* in zephyr/dts/arm/st/h5/stm32h5.dtsi:623 */
			#size-cells = < 0x0 >;                                      /* in zephyr/dts/arm/st/h5/stm32h5.dtsi:624 */
			reg = < 0x40003c00 0x400 >;                                 /* in zephyr/dts/arm/st/h5/stm32h5.dtsi:625 */
			clocks = < &rcc 0x9c 0x8000 >,
			         < &rcc 0xd 0x1c600e0 >;                            /* in zephyr/dts/arm/st/h5/stm32h5.dtsi:626 */
			dmas = < &gpdma1 0x4 0xb 0x22c40 &gpdma1 0x5 0xa 0x22c80 >; /* in zephyr/dts/arm/st/h5/stm32h5.dtsi:628 */
			dma-names = "tx",
			            "rx";                                           /* in zephyr/dts/arm/st/h5/stm32h5.dtsi:632 */
			interrupts = < 0x39 0x3 >;                                  /* in zephyr/dts/arm/st/h5/stm32h5.dtsi:633 */
			status = "disabled";                                        /* in zephyr/dts/arm/st/h5/stm32h5.dtsi:634 */
		};

		/* node '/soc/sai1@40015404' defined in zephyr/dts/arm/st/h5/stm32h5.dtsi:637 */
		sai1_a: sai1@40015404 {
			compatible = "st,stm32-sai";     /* in zephyr/dts/arm/st/h5/stm32h5.dtsi:638 */
			#address-cells = < 0x1 >;        /* in zephyr/dts/arm/st/h5/stm32h5.dtsi:639 */
			#size-cells = < 0x0 >;           /* in zephyr/dts/arm/st/h5/stm32h5.dtsi:640 */
			reg = < 0x40015404 0x20 >;       /* in zephyr/dts/arm/st/h5/stm32h5.dtsi:641 */
			clocks = < &rcc 0xa4 0x200000 >,
			         < &rcc 0xf 0x1d000e8 >; /* in zephyr/dts/arm/st/h5/stm32h5.dtsi:642 */
			dmas = < &gpdma1 0x1 0x35 0x0 >; /* in zephyr/dts/arm/st/h5/stm32h5.dtsi:644 */
			status = "disabled";             /* in zephyr/dts/arm/st/h5/stm32h5.dtsi:645 */
		};

		/* node '/soc/sai1@40015424' defined in zephyr/dts/arm/st/h5/stm32h5.dtsi:648 */
		sai1_b: sai1@40015424 {
			compatible = "st,stm32-sai";     /* in zephyr/dts/arm/st/h5/stm32h5.dtsi:649 */
			#address-cells = < 0x1 >;        /* in zephyr/dts/arm/st/h5/stm32h5.dtsi:650 */
			#size-cells = < 0x0 >;           /* in zephyr/dts/arm/st/h5/stm32h5.dtsi:651 */
			reg = < 0x40015424 0x20 >;       /* in zephyr/dts/arm/st/h5/stm32h5.dtsi:652 */
			clocks = < &rcc 0xa4 0x200000 >,
			         < &rcc 0xf 0x1d000e8 >; /* in zephyr/dts/arm/st/h5/stm32h5.dtsi:653 */
			dmas = < &gpdma1 0x0 0x36 0x0 >; /* in zephyr/dts/arm/st/h5/stm32h5.dtsi:655 */
			status = "disabled";             /* in zephyr/dts/arm/st/h5/stm32h5.dtsi:656 */
		};

		/* node '/soc/usb@40016000' defined in zephyr/dts/arm/st/h5/stm32h5.dtsi:659 */
		usb: zephyr_udc0: usb@40016000 {
			compatible = "st,stm32-usb";               /* in zephyr/dts/arm/st/h5/stm32h5.dtsi:660 */
			reg = < 0x40016000 0x400 >;                /* in zephyr/dts/arm/st/h5/stm32h5.dtsi:661 */
			interrupts = < 0x4a 0x0 >;                 /* in zephyr/dts/arm/st/h5/stm32h5.dtsi:662 */
			interrupt-names = "usb";                   /* in zephyr/dts/arm/st/h5/stm32h5.dtsi:663 */
			num-bidir-endpoints = < 0x8 >;             /* in zephyr/dts/arm/st/h5/stm32h5.dtsi:664 */
			ram-size = < 0x800 >;                      /* in zephyr/dts/arm/st/h5/stm32h5.dtsi:665 */
			maximum-speed = "full-speed";              /* in zephyr/dts/arm/st/h5/stm32h5.dtsi:666 */
			phys = < &usb_fs_phy >;                    /* in zephyr/dts/arm/st/h5/stm32h5.dtsi:667 */
			clocks = < &rcc 0xa4 0x1000000 >,
			         < &rcc 0x7 0x18c400e4 >;          /* in zephyr/dts/arm/st/h5/stm32h5.dtsi:668 */
			pinctrl-0 = < &usb_dm_pa11 &usb_dp_pa12 >; /* in zephyr/boards/st/nucleo_h563zi/nucleo_h563zi-common.dtsi:206 */
			pinctrl-names = "default";                 /* in zephyr/boards/st/nucleo_h563zi/nucleo_h563zi-common.dtsi:207 */
			status = "okay";                           /* in zephyr/boards/st/nucleo_h563zi/nucleo_h563zi-common.dtsi:208 */
		};

		/* node '/soc/digi_dietemp@40008c00' defined in zephyr/dts/arm/st/h5/stm32h5.dtsi:673 */
		digi_die_temp: digi_dietemp@40008c00 {
			compatible = "st,stm32-digi-temp"; /* in zephyr/dts/arm/st/h5/stm32h5.dtsi:674 */
			reg = < 0x40008c00 0x400 >;        /* in zephyr/dts/arm/st/h5/stm32h5.dtsi:675 */
			interrupts = < 0x71 0x0 >;         /* in zephyr/dts/arm/st/h5/stm32h5.dtsi:676 */
			interrupt-names = "digi_temp";     /* in zephyr/dts/arm/st/h5/stm32h5.dtsi:677 */
			clocks = < &rcc 0xa0 0x8 >;        /* in zephyr/dts/arm/st/h5/stm32h5.dtsi:678 */
			status = "disabled";               /* in zephyr/dts/arm/st/h5/stm32h5.dtsi:679 */
		};

		/* node '/soc/memory@20000000' defined in zephyr/dts/arm/st/h5/stm32h562.dtsi:60 */
		sram1: memory@20000000 {
			compatible = "zephyr,memory-region",
			             "mmio-sram";            /* in zephyr/dts/arm/st/h5/stm32h562.dtsi:61 */
			reg = < 0x20000000 0x40000 >;        /* in zephyr/dts/arm/st/h5/stm32h562.dtsi:62 */
			zephyr,memory-region = "SRAM1";      /* in zephyr/dts/arm/st/h5/stm32h562.dtsi:63 */
		};

		/* node '/soc/memory@20040000' defined in zephyr/dts/arm/st/h5/stm32h562.dtsi:66 */
		sram2: memory@20040000 {
			compatible = "zephyr,memory-region",
			             "mmio-sram";            /* in zephyr/dts/arm/st/h5/stm32h562.dtsi:67 */
			reg = < 0x20040000 0x10000 >;        /* in zephyr/dts/arm/st/h5/stm32h562.dtsi:68 */
			zephyr,memory-region = "SRAM2";      /* in zephyr/dts/arm/st/h5/stm32h562.dtsi:69 */
		};

		/* node '/soc/memory@20050000' defined in zephyr/dts/arm/st/h5/stm32h562.dtsi:72 */
		sram3: memory@20050000 {
			compatible = "zephyr,memory-region",
			             "mmio-sram";            /* in zephyr/dts/arm/st/h5/stm32h562.dtsi:73 */
			reg = < 0x20050000 0x50000 >;        /* in zephyr/dts/arm/st/h5/stm32h562.dtsi:74 */
			zephyr,memory-region = "SRAM3";      /* in zephyr/dts/arm/st/h5/stm32h562.dtsi:75 */
		};

		/* node '/soc/timers@44004800' defined in zephyr/dts/arm/st/h5/stm32h562.dtsi:82 */
		lptim3: timers@44004800 {
			compatible = "st,stm32-lptim"; /* in zephyr/dts/arm/st/h5/stm32h562.dtsi:83 */
			clocks = < &rcc 0xa8 0x1000 >; /* in zephyr/dts/arm/st/h5/stm32h562.dtsi:84 */
			#address-cells = < 0x1 >;      /* in zephyr/dts/arm/st/h5/stm32h562.dtsi:85 */
			#size-cells = < 0x0 >;         /* in zephyr/dts/arm/st/h5/stm32h562.dtsi:86 */
			reg = < 0x44004800 0x400 >;    /* in zephyr/dts/arm/st/h5/stm32h562.dtsi:87 */
			interrupts = < 0x7f 0x1 >;     /* in zephyr/dts/arm/st/h5/stm32h562.dtsi:88 */
			interrupt-names = "wakeup";    /* in zephyr/dts/arm/st/h5/stm32h562.dtsi:89 */
			status = "disabled";           /* in zephyr/dts/arm/st/h5/stm32h562.dtsi:90 */
		};

		/* node '/soc/timers@44004c00' defined in zephyr/dts/arm/st/h5/stm32h562.dtsi:93 */
		lptim4: stm32_lp_tick_source: timers@44004c00 {
			compatible = "st,stm32-lptim";    /* in zephyr/dts/arm/st/h5/stm32h562.dtsi:94 */
			#address-cells = < 0x1 >;         /* in zephyr/dts/arm/st/h5/stm32h562.dtsi:96 */
			#size-cells = < 0x0 >;            /* in zephyr/dts/arm/st/h5/stm32h562.dtsi:97 */
			reg = < 0x44004c00 0x400 >;       /* in zephyr/dts/arm/st/h5/stm32h562.dtsi:98 */
			interrupts = < 0x80 0x1 >;        /* in zephyr/dts/arm/st/h5/stm32h562.dtsi:99 */
			interrupt-names = "wakeup";       /* in zephyr/dts/arm/st/h5/stm32h562.dtsi:100 */
			clocks = < &rcc 0xa8 0x2000 >,
			         < &rcc 0x3 0x21d400dc >; /* in zephyr/boards/st/nucleo_h563zi/nucleo_h563zi-common.dtsi:224 */
			status = "okay";                  /* in zephyr/boards/st/nucleo_h563zi/nucleo_h563zi-common.dtsi:226 */
		};

		/* node '/soc/timers@44005000' defined in zephyr/dts/arm/st/h5/stm32h562.dtsi:104 */
		lptim5: timers@44005000 {
			compatible = "st,stm32-lptim"; /* in zephyr/dts/arm/st/h5/stm32h562.dtsi:105 */
			clocks = < &rcc 0xa8 0x4000 >; /* in zephyr/dts/arm/st/h5/stm32h562.dtsi:106 */
			#address-cells = < 0x1 >;      /* in zephyr/dts/arm/st/h5/stm32h562.dtsi:107 */
			#size-cells = < 0x0 >;         /* in zephyr/dts/arm/st/h5/stm32h562.dtsi:108 */
			reg = < 0x44005000 0x400 >;    /* in zephyr/dts/arm/st/h5/stm32h562.dtsi:109 */
			interrupts = < 0x81 0x1 >;     /* in zephyr/dts/arm/st/h5/stm32h562.dtsi:110 */
			interrupt-names = "wakeup";    /* in zephyr/dts/arm/st/h5/stm32h562.dtsi:111 */
			status = "disabled";           /* in zephyr/dts/arm/st/h5/stm32h562.dtsi:112 */
		};

		/* node '/soc/timers@44005400' defined in zephyr/dts/arm/st/h5/stm32h562.dtsi:115 */
		lptim6: timers@44005400 {
			compatible = "st,stm32-lptim"; /* in zephyr/dts/arm/st/h5/stm32h562.dtsi:116 */
			clocks = < &rcc 0xa8 0x8000 >; /* in zephyr/dts/arm/st/h5/stm32h562.dtsi:117 */
			#address-cells = < 0x1 >;      /* in zephyr/dts/arm/st/h5/stm32h562.dtsi:118 */
			#size-cells = < 0x0 >;         /* in zephyr/dts/arm/st/h5/stm32h562.dtsi:119 */
			reg = < 0x44005400 0x400 >;    /* in zephyr/dts/arm/st/h5/stm32h562.dtsi:120 */
			interrupts = < 0x82 0x1 >;     /* in zephyr/dts/arm/st/h5/stm32h562.dtsi:121 */
			interrupt-names = "wakeup";    /* in zephyr/dts/arm/st/h5/stm32h562.dtsi:122 */
			status = "disabled";           /* in zephyr/dts/arm/st/h5/stm32h562.dtsi:123 */
		};

		/* node '/soc/serial@40004c00' defined in zephyr/dts/arm/st/h5/stm32h562.dtsi:126 */
		uart4: serial@40004c00 {
			compatible = "st,stm32-uart";   /* in zephyr/dts/arm/st/h5/stm32h562.dtsi:127 */
			reg = < 0x40004c00 0x400 >;     /* in zephyr/dts/arm/st/h5/stm32h562.dtsi:128 */
			clocks = < &rcc 0x9c 0x80000 >; /* in zephyr/dts/arm/st/h5/stm32h562.dtsi:129 */
			resets = < &rctl 0xe93 >;       /* in zephyr/dts/arm/st/h5/stm32h562.dtsi:130 */
			interrupts = < 0x3d 0x0 >;      /* in zephyr/dts/arm/st/h5/stm32h562.dtsi:131 */
			status = "disabled";            /* in zephyr/dts/arm/st/h5/stm32h562.dtsi:132 */
		};

		/* node '/soc/serial@40005000' defined in zephyr/dts/arm/st/h5/stm32h562.dtsi:135 */
		uart5: serial@40005000 {
			compatible = "st,stm32-uart";    /* in zephyr/dts/arm/st/h5/stm32h562.dtsi:136 */
			reg = < 0x40005000 0x400 >;      /* in zephyr/dts/arm/st/h5/stm32h562.dtsi:137 */
			clocks = < &rcc 0x9c 0x100000 >; /* in zephyr/dts/arm/st/h5/stm32h562.dtsi:138 */
			resets = < &rctl 0xe94 >;        /* in zephyr/dts/arm/st/h5/stm32h562.dtsi:139 */
			interrupts = < 0x3e 0x0 >;       /* in zephyr/dts/arm/st/h5/stm32h562.dtsi:140 */
			status = "disabled";             /* in zephyr/dts/arm/st/h5/stm32h562.dtsi:141 */
		};

		/* node '/soc/serial@40007800' defined in zephyr/dts/arm/st/h5/stm32h562.dtsi:144 */
		uart7: serial@40007800 {
			compatible = "st,stm32-uart";      /* in zephyr/dts/arm/st/h5/stm32h562.dtsi:145 */
			reg = < 0x40007800 0x400 >;        /* in zephyr/dts/arm/st/h5/stm32h562.dtsi:146 */
			clocks = < &rcc 0x9c 0x40000000 >; /* in zephyr/dts/arm/st/h5/stm32h562.dtsi:147 */
			resets = < &rctl 0xe9e >;          /* in zephyr/dts/arm/st/h5/stm32h562.dtsi:148 */
			interrupts = < 0x62 0x0 >;         /* in zephyr/dts/arm/st/h5/stm32h562.dtsi:149 */
			status = "disabled";               /* in zephyr/dts/arm/st/h5/stm32h562.dtsi:150 */
		};

		/* node '/soc/serial@40007c00' defined in zephyr/dts/arm/st/h5/stm32h562.dtsi:153 */
		uart8: serial@40007c00 {
			compatible = "st,stm32-uart";      /* in zephyr/dts/arm/st/h5/stm32h562.dtsi:154 */
			reg = < 0x40007c00 0x400 >;        /* in zephyr/dts/arm/st/h5/stm32h562.dtsi:155 */
			clocks = < &rcc 0x9c 0x80000000 >; /* in zephyr/dts/arm/st/h5/stm32h562.dtsi:156 */
			resets = < &rctl 0xe9f >;          /* in zephyr/dts/arm/st/h5/stm32h562.dtsi:157 */
			interrupts = < 0x63 0x0 >;         /* in zephyr/dts/arm/st/h5/stm32h562.dtsi:158 */
			status = "disabled";               /* in zephyr/dts/arm/st/h5/stm32h562.dtsi:159 */
		};

		/* node '/soc/serial@40008000' defined in zephyr/dts/arm/st/h5/stm32h562.dtsi:162 */
		uart9: serial@40008000 {
			compatible = "st,stm32-uart"; /* in zephyr/dts/arm/st/h5/stm32h562.dtsi:163 */
			reg = < 0x40008000 0x400 >;   /* in zephyr/dts/arm/st/h5/stm32h562.dtsi:164 */
			clocks = < &rcc 0xa0 0x1 >;   /* in zephyr/dts/arm/st/h5/stm32h562.dtsi:165 */
			resets = < &rctl 0xf00 >;     /* in zephyr/dts/arm/st/h5/stm32h562.dtsi:166 */
			interrupts = < 0x64 0x0 >;    /* in zephyr/dts/arm/st/h5/stm32h562.dtsi:167 */
			status = "disabled";          /* in zephyr/dts/arm/st/h5/stm32h562.dtsi:168 */
		};

		/* node '/soc/serial@40006400' defined in zephyr/dts/arm/st/h5/stm32h562.dtsi:171 */
		usart6: serial@40006400 {
			compatible = "st,stm32-usart",
			             "st,stm32-uart";     /* in zephyr/dts/arm/st/h5/stm32h562.dtsi:172 */
			reg = < 0x40006400 0x400 >;       /* in zephyr/dts/arm/st/h5/stm32h562.dtsi:173 */
			clocks = < &rcc 0x9c 0x2000000 >; /* in zephyr/dts/arm/st/h5/stm32h562.dtsi:174 */
			resets = < &rctl 0xe99 >;         /* in zephyr/dts/arm/st/h5/stm32h562.dtsi:175 */
			interrupts = < 0x55 0x0 >;        /* in zephyr/dts/arm/st/h5/stm32h562.dtsi:176 */
			status = "disabled";              /* in zephyr/dts/arm/st/h5/stm32h562.dtsi:177 */
		};

		/* node '/soc/serial@40006800' defined in zephyr/dts/arm/st/h5/stm32h562.dtsi:180 */
		usart10: serial@40006800 {
			compatible = "st,stm32-usart",
			             "st,stm32-uart";     /* in zephyr/dts/arm/st/h5/stm32h562.dtsi:181 */
			reg = < 0x40006800 0x400 >;       /* in zephyr/dts/arm/st/h5/stm32h562.dtsi:182 */
			clocks = < &rcc 0x9c 0x4000000 >; /* in zephyr/dts/arm/st/h5/stm32h562.dtsi:183 */
			resets = < &rctl 0xe9a >;         /* in zephyr/dts/arm/st/h5/stm32h562.dtsi:184 */
			interrupts = < 0x56 0x0 >;        /* in zephyr/dts/arm/st/h5/stm32h562.dtsi:185 */
			status = "disabled";              /* in zephyr/dts/arm/st/h5/stm32h562.dtsi:186 */
		};

		/* node '/soc/serial@40006c00' defined in zephyr/dts/arm/st/h5/stm32h562.dtsi:189 */
		usart11: serial@40006c00 {
			compatible = "st,stm32-usart",
			             "st,stm32-uart";     /* in zephyr/dts/arm/st/h5/stm32h562.dtsi:190 */
			reg = < 0x40006c00 0x400 >;       /* in zephyr/dts/arm/st/h5/stm32h562.dtsi:191 */
			clocks = < &rcc 0x9c 0x8000000 >; /* in zephyr/dts/arm/st/h5/stm32h562.dtsi:192 */
			resets = < &rctl 0xe9b >;         /* in zephyr/dts/arm/st/h5/stm32h562.dtsi:193 */
			interrupts = < 0x57 0x0 >;        /* in zephyr/dts/arm/st/h5/stm32h562.dtsi:194 */
			status = "disabled";              /* in zephyr/dts/arm/st/h5/stm32h562.dtsi:195 */
		};

		/* node '/soc/serial@40008400' defined in zephyr/dts/arm/st/h5/stm32h562.dtsi:198 */
		uart12: serial@40008400 {
			compatible = "st,stm32-uart"; /* in zephyr/dts/arm/st/h5/stm32h562.dtsi:199 */
			reg = < 0x40008400 0x400 >;   /* in zephyr/dts/arm/st/h5/stm32h562.dtsi:200 */
			clocks = < &rcc 0xa0 0x2 >;   /* in zephyr/dts/arm/st/h5/stm32h562.dtsi:201 */
			resets = < &rctl 0xf01 >;     /* in zephyr/dts/arm/st/h5/stm32h562.dtsi:202 */
			interrupts = < 0x65 0x0 >;    /* in zephyr/dts/arm/st/h5/stm32h562.dtsi:203 */
			status = "disabled";          /* in zephyr/dts/arm/st/h5/stm32h562.dtsi:204 */
		};

		/* node '/soc/i2c@44002800' defined in zephyr/dts/arm/st/h5/stm32h562.dtsi:207 */
		i2c3: i2c@44002800 {
			compatible = "st,stm32-i2c-v2"; /* in zephyr/dts/arm/st/h5/stm32h562.dtsi:208 */
			clock-frequency = < 0x186a0 >;  /* in zephyr/dts/arm/st/h5/stm32h562.dtsi:209 */
			#address-cells = < 0x1 >;       /* in zephyr/dts/arm/st/h5/stm32h562.dtsi:210 */
			#size-cells = < 0x0 >;          /* in zephyr/dts/arm/st/h5/stm32h562.dtsi:211 */
			reg = < 0x44002800 0x400 >;     /* in zephyr/dts/arm/st/h5/stm32h562.dtsi:212 */
			clocks = < &rcc 0xa8 0x80 >;    /* in zephyr/dts/arm/st/h5/stm32h562.dtsi:213 */
			interrupts = < 0x50 0x0 >,
			             < 0x51 0x0 >;      /* in zephyr/dts/arm/st/h5/stm32h562.dtsi:214 */
			interrupt-names = "event",
			                  "error";      /* in zephyr/dts/arm/st/h5/stm32h562.dtsi:215 */
			status = "disabled";            /* in zephyr/dts/arm/st/h5/stm32h562.dtsi:216 */
			phandle = < 0x2a >;             /* in zephyr/dts/arm/st/h5/stm32h562.dtsi:517 */
		};

		/* node '/soc/i2c@44002c00' defined in zephyr/dts/arm/st/h5/stm32h562.dtsi:219 */
		i2c4: i2c@44002c00 {
			compatible = "st,stm32-i2c-v2"; /* in zephyr/dts/arm/st/h5/stm32h562.dtsi:220 */
			clock-frequency = < 0x186a0 >;  /* in zephyr/dts/arm/st/h5/stm32h562.dtsi:221 */
			#address-cells = < 0x1 >;       /* in zephyr/dts/arm/st/h5/stm32h562.dtsi:222 */
			#size-cells = < 0x0 >;          /* in zephyr/dts/arm/st/h5/stm32h562.dtsi:223 */
			reg = < 0x44002c00 0x400 >;     /* in zephyr/dts/arm/st/h5/stm32h562.dtsi:224 */
			clocks = < &rcc 0xa8 0x100 >;   /* in zephyr/dts/arm/st/h5/stm32h562.dtsi:225 */
			interrupts = < 0x7d 0x0 >,
			             < 0x7e 0x0 >;      /* in zephyr/dts/arm/st/h5/stm32h562.dtsi:226 */
			interrupt-names = "event",
			                  "error";      /* in zephyr/dts/arm/st/h5/stm32h562.dtsi:227 */
			status = "disabled";            /* in zephyr/dts/arm/st/h5/stm32h562.dtsi:228 */
			phandle = < 0x2b >;             /* in zephyr/dts/arm/st/h5/stm32h562.dtsi:525 */
		};

		/* node '/soc/spi@40014c00' defined in zephyr/dts/arm/st/h5/stm32h562.dtsi:231 */
		spi4: spi@40014c00 {
			compatible = "st,stm32h7-spi",
			             "st,stm32-spi-fifo",
			             "st,stm32-spi";      /* in zephyr/dts/arm/st/h5/stm32h562.dtsi:232 */
			#address-cells = < 0x1 >;         /* in zephyr/dts/arm/st/h5/stm32h562.dtsi:233 */
			#size-cells = < 0x0 >;            /* in zephyr/dts/arm/st/h5/stm32h562.dtsi:234 */
			reg = < 0x40014c00 0x400 >;       /* in zephyr/dts/arm/st/h5/stm32h562.dtsi:235 */
			interrupts = < 0x52 0x5 >;        /* in zephyr/dts/arm/st/h5/stm32h562.dtsi:236 */
			clocks = < &rcc 0xa4 0x80000 >;   /* in zephyr/dts/arm/st/h5/stm32h562.dtsi:237 */
			status = "disabled";              /* in zephyr/dts/arm/st/h5/stm32h562.dtsi:238 */
		};

		/* node '/soc/spi@44002000' defined in zephyr/dts/arm/st/h5/stm32h562.dtsi:241 */
		spi5: spi@44002000 {
			compatible = "st,stm32h7-spi",
			             "st,stm32-spi-fifo",
			             "st,stm32-spi";      /* in zephyr/dts/arm/st/h5/stm32h562.dtsi:242 */
			#address-cells = < 0x1 >;         /* in zephyr/dts/arm/st/h5/stm32h562.dtsi:243 */
			#size-cells = < 0x0 >;            /* in zephyr/dts/arm/st/h5/stm32h562.dtsi:244 */
			reg = < 0x44002000 0x400 >;       /* in zephyr/dts/arm/st/h5/stm32h562.dtsi:245 */
			interrupts = < 0x53 0x5 >;        /* in zephyr/dts/arm/st/h5/stm32h562.dtsi:246 */
			clocks = < &rcc 0xa8 0x20 >;      /* in zephyr/dts/arm/st/h5/stm32h562.dtsi:247 */
			status = "disabled";              /* in zephyr/dts/arm/st/h5/stm32h562.dtsi:248 */
		};

		/* node '/soc/spi@40015000' defined in zephyr/dts/arm/st/h5/stm32h562.dtsi:251 */
		spi6: spi@40015000 {
			compatible = "st,stm32h7-spi",
			             "st,stm32-spi-fifo",
			             "st,stm32-spi";      /* in zephyr/dts/arm/st/h5/stm32h562.dtsi:252 */
			#address-cells = < 0x1 >;         /* in zephyr/dts/arm/st/h5/stm32h562.dtsi:253 */
			#size-cells = < 0x0 >;            /* in zephyr/dts/arm/st/h5/stm32h562.dtsi:254 */
			reg = < 0x40015000 0x400 >;       /* in zephyr/dts/arm/st/h5/stm32h562.dtsi:255 */
			interrupts = < 0x54 0x5 >;        /* in zephyr/dts/arm/st/h5/stm32h562.dtsi:256 */
			clocks = < &rcc 0xa4 0x100000 >;  /* in zephyr/dts/arm/st/h5/stm32h562.dtsi:257 */
			status = "disabled";              /* in zephyr/dts/arm/st/h5/stm32h562.dtsi:258 */
		};

		/* node '/soc/spi@47001400' defined in zephyr/dts/arm/st/h5/stm32h562.dtsi:261 */
		xspi1: spi@47001400 {
			compatible = "st,stm32-xspi";    /* in zephyr/dts/arm/st/h5/stm32h562.dtsi:262 */
			reg = < 0x47001400 0x400 >,
			      < 0x90000000 0x10000000 >; /* in zephyr/dts/arm/st/h5/stm32h562.dtsi:263 */
			interrupts = < 0x4e 0x0 >;       /* in zephyr/dts/arm/st/h5/stm32h562.dtsi:264 */
			clock-names = "xspix",
			              "xspi-ker";        /* in zephyr/dts/arm/st/h5/stm32h562.dtsi:265 */
			clocks = < &rcc 0x94 0x100000 >,
			         < &rcc 0xd 0x8c000e4 >; /* in zephyr/dts/arm/st/h5/stm32h562.dtsi:266 */
			#address-cells = < 0x1 >;        /* in zephyr/dts/arm/st/h5/stm32h562.dtsi:268 */
			#size-cells = < 0x0 >;           /* in zephyr/dts/arm/st/h5/stm32h562.dtsi:269 */
			status = "disabled";             /* in zephyr/dts/arm/st/h5/stm32h562.dtsi:270 */
		};

		/* node '/soc/adc@42028100' defined in zephyr/dts/arm/st/h5/stm32h562.dtsi:273 */
		adc2: adc@42028100 {
			compatible = "st,stm32-adc";                                /* in zephyr/dts/arm/st/h5/stm32h562.dtsi:274 */
			reg = < 0x42028100 0x400 >;                                 /* in zephyr/dts/arm/st/h5/stm32h562.dtsi:275 */
			clocks = < &rcc 0x8c 0x400 >;                               /* in zephyr/dts/arm/st/h5/stm32h562.dtsi:276 */
			interrupts = < 0x45 0x0 >;                                  /* in zephyr/dts/arm/st/h5/stm32h562.dtsi:277 */
			status = "disabled";                                        /* in zephyr/dts/arm/st/h5/stm32h562.dtsi:278 */
			vref-mv = < 0xce4 >;                                        /* in zephyr/dts/arm/st/h5/stm32h562.dtsi:279 */
			#io-channel-cells = < 0x1 >;                                /* in zephyr/dts/arm/st/h5/stm32h562.dtsi:280 */
			resolutions = < 0x60630c 0x51630c 0x42630c 0x33630c >;      /* in zephyr/dts/arm/st/h5/stm32h562.dtsi:281 */
			sampling-times = < 0x3 0x7 0xd 0x19 0x30 0x5d 0xf8 0x281 >; /* in zephyr/dts/arm/st/h5/stm32h562.dtsi:285 */
			st,adc-sequencer = "FULLY_CONFIGURABLE";                    /* in zephyr/dts/arm/st/h5/stm32h562.dtsi:286 */
			st,adc-oversampler = "OVERSAMPLER_MINIMAL";                 /* in zephyr/dts/arm/st/h5/stm32h562.dtsi:287 */
		};

		/* node '/soc/timers@40000800' defined in zephyr/dts/arm/st/h5/stm32h562.dtsi:290 */
		timers4: timers@40000800 {
			compatible = "st,stm32-timers"; /* in zephyr/dts/arm/st/h5/stm32h562.dtsi:291 */
			reg = < 0x40000800 0x400 >;     /* in zephyr/dts/arm/st/h5/stm32h562.dtsi:292 */
			clocks = < &rcc 0x9c 0x4 >;     /* in zephyr/dts/arm/st/h5/stm32h562.dtsi:293 */
			resets = < &rctl 0xe82 >;       /* in zephyr/dts/arm/st/h5/stm32h562.dtsi:294 */
			interrupts = < 0x2f 0x0 >;      /* in zephyr/dts/arm/st/h5/stm32h562.dtsi:295 */
			interrupt-names = "global";     /* in zephyr/dts/arm/st/h5/stm32h562.dtsi:296 */
			status = "disabled";            /* in zephyr/dts/arm/st/h5/stm32h562.dtsi:297 */

			/* node '/soc/timers@40000800/pwm' defined in zephyr/dts/arm/st/h5/stm32h562.dtsi:299 */
			pwm {
				compatible = "st,stm32-pwm"; /* in zephyr/dts/arm/st/h5/stm32h562.dtsi:300 */
				status = "disabled";         /* in zephyr/dts/arm/st/h5/stm32h562.dtsi:301 */
				#pwm-cells = < 0x3 >;        /* in zephyr/dts/arm/st/h5/stm32h562.dtsi:302 */
			};

			/* node '/soc/timers@40000800/counter' defined in zephyr/dts/arm/st/h5/stm32h562.dtsi:305 */
			counter {
				compatible = "st,stm32-counter"; /* in zephyr/dts/arm/st/h5/stm32h562.dtsi:306 */
				status = "disabled";             /* in zephyr/dts/arm/st/h5/stm32h562.dtsi:307 */
			};
		};

		/* node '/soc/timers@40000c00' defined in zephyr/dts/arm/st/h5/stm32h562.dtsi:311 */
		timers5: timers@40000c00 {
			compatible = "st,stm32-timers"; /* in zephyr/dts/arm/st/h5/stm32h562.dtsi:312 */
			reg = < 0x40000c00 0x400 >;     /* in zephyr/dts/arm/st/h5/stm32h562.dtsi:313 */
			clocks = < &rcc 0x9c 0x8 >;     /* in zephyr/dts/arm/st/h5/stm32h562.dtsi:314 */
			resets = < &rctl 0xe83 >;       /* in zephyr/dts/arm/st/h5/stm32h562.dtsi:315 */
			interrupts = < 0x30 0x0 >;      /* in zephyr/dts/arm/st/h5/stm32h562.dtsi:316 */
			interrupt-names = "global";     /* in zephyr/dts/arm/st/h5/stm32h562.dtsi:317 */
			status = "disabled";            /* in zephyr/dts/arm/st/h5/stm32h562.dtsi:318 */

			/* node '/soc/timers@40000c00/pwm' defined in zephyr/dts/arm/st/h5/stm32h562.dtsi:320 */
			pwm {
				compatible = "st,stm32-pwm"; /* in zephyr/dts/arm/st/h5/stm32h562.dtsi:321 */
				status = "disabled";         /* in zephyr/dts/arm/st/h5/stm32h562.dtsi:322 */
				#pwm-cells = < 0x3 >;        /* in zephyr/dts/arm/st/h5/stm32h562.dtsi:323 */
			};

			/* node '/soc/timers@40000c00/counter' defined in zephyr/dts/arm/st/h5/stm32h562.dtsi:326 */
			counter {
				compatible = "st,stm32-counter"; /* in zephyr/dts/arm/st/h5/stm32h562.dtsi:327 */
				status = "disabled";             /* in zephyr/dts/arm/st/h5/stm32h562.dtsi:328 */
			};
		};

		/* node '/soc/timers@40013400' defined in zephyr/dts/arm/st/h5/stm32h562.dtsi:332 */
		timers8: timers@40013400 {
			compatible = "st,stm32-timers"; /* in zephyr/dts/arm/st/h5/stm32h562.dtsi:333 */
			reg = < 0x40013400 0x400 >;     /* in zephyr/dts/arm/st/h5/stm32h562.dtsi:334 */
			clocks = < &rcc 0xa4 0x2000 >;  /* in zephyr/dts/arm/st/h5/stm32h562.dtsi:335 */
			resets = < &rctl 0xf8d >;       /* in zephyr/dts/arm/st/h5/stm32h562.dtsi:336 */
			interrupts = < 0x41 0x0 >,
			             < 0x42 0x0 >,
			             < 0x43 0x0 >,
			             < 0x44 0x0 >;      /* in zephyr/dts/arm/st/h5/stm32h562.dtsi:337 */
			interrupt-names = "brk",
			                  "up",
			                  "trgcom",
			                  "cc";         /* in zephyr/dts/arm/st/h5/stm32h562.dtsi:338 */
			status = "disabled";            /* in zephyr/dts/arm/st/h5/stm32h562.dtsi:339 */

			/* node '/soc/timers@40013400/pwm' defined in zephyr/dts/arm/st/h5/stm32h562.dtsi:341 */
			pwm {
				compatible = "st,stm32-pwm"; /* in zephyr/dts/arm/st/h5/stm32h562.dtsi:342 */
				status = "disabled";         /* in zephyr/dts/arm/st/h5/stm32h562.dtsi:343 */
				#pwm-cells = < 0x3 >;        /* in zephyr/dts/arm/st/h5/stm32h562.dtsi:344 */
			};
		};

		/* node '/soc/timers@40001800' defined in zephyr/dts/arm/st/h5/stm32h562.dtsi:348 */
		timers12: timers@40001800 {
			compatible = "st,stm32-timers"; /* in zephyr/dts/arm/st/h5/stm32h562.dtsi:349 */
			reg = < 0x40001800 0x400 >;     /* in zephyr/dts/arm/st/h5/stm32h562.dtsi:350 */
			clocks = < &rcc 0x9c 0x40 >;    /* in zephyr/dts/arm/st/h5/stm32h562.dtsi:351 */
			resets = < &rctl 0xe86 >;       /* in zephyr/dts/arm/st/h5/stm32h562.dtsi:352 */
			interrupts = < 0x78 0x0 >;      /* in zephyr/dts/arm/st/h5/stm32h562.dtsi:353 */
			interrupt-names = "global";     /* in zephyr/dts/arm/st/h5/stm32h562.dtsi:354 */
			status = "disabled";            /* in zephyr/dts/arm/st/h5/stm32h562.dtsi:355 */

			/* node '/soc/timers@40001800/pwm' defined in zephyr/dts/arm/st/h5/stm32h562.dtsi:357 */
			pwm {
				compatible = "st,stm32-pwm"; /* in zephyr/dts/arm/st/h5/stm32h562.dtsi:358 */
				status = "disabled";         /* in zephyr/dts/arm/st/h5/stm32h562.dtsi:359 */
				#pwm-cells = < 0x3 >;        /* in zephyr/dts/arm/st/h5/stm32h562.dtsi:360 */
			};

			/* node '/soc/timers@40001800/counter' defined in zephyr/dts/arm/st/h5/stm32h562.dtsi:363 */
			counter {
				compatible = "st,stm32-counter"; /* in zephyr/dts/arm/st/h5/stm32h562.dtsi:364 */
				status = "disabled";             /* in zephyr/dts/arm/st/h5/stm32h562.dtsi:365 */
			};
		};

		/* node '/soc/timers@40001c00' defined in zephyr/dts/arm/st/h5/stm32h562.dtsi:369 */
		timers13: timers@40001c00 {
			compatible = "st,stm32-timers"; /* in zephyr/dts/arm/st/h5/stm32h562.dtsi:370 */
			reg = < 0x40001c00 0x400 >;     /* in zephyr/dts/arm/st/h5/stm32h562.dtsi:371 */
			clocks = < &rcc 0x9c 0x80 >;    /* in zephyr/dts/arm/st/h5/stm32h562.dtsi:372 */
			resets = < &rctl 0xe87 >;       /* in zephyr/dts/arm/st/h5/stm32h562.dtsi:373 */
			interrupts = < 0x79 0x0 >;      /* in zephyr/dts/arm/st/h5/stm32h562.dtsi:374 */
			interrupt-names = "global";     /* in zephyr/dts/arm/st/h5/stm32h562.dtsi:375 */
			status = "disabled";            /* in zephyr/dts/arm/st/h5/stm32h562.dtsi:376 */

			/* node '/soc/timers@40001c00/pwm' defined in zephyr/dts/arm/st/h5/stm32h562.dtsi:378 */
			pwm {
				compatible = "st,stm32-pwm"; /* in zephyr/dts/arm/st/h5/stm32h562.dtsi:379 */
				status = "disabled";         /* in zephyr/dts/arm/st/h5/stm32h562.dtsi:380 */
				#pwm-cells = < 0x3 >;        /* in zephyr/dts/arm/st/h5/stm32h562.dtsi:381 */
			};

			/* node '/soc/timers@40001c00/counter' defined in zephyr/dts/arm/st/h5/stm32h562.dtsi:384 */
			counter {
				compatible = "st,stm32-counter"; /* in zephyr/dts/arm/st/h5/stm32h562.dtsi:385 */
				status = "disabled";             /* in zephyr/dts/arm/st/h5/stm32h562.dtsi:386 */
			};
		};

		/* node '/soc/timers@40002000' defined in zephyr/dts/arm/st/h5/stm32h562.dtsi:390 */
		timers14: timers@40002000 {
			compatible = "st,stm32-timers"; /* in zephyr/dts/arm/st/h5/stm32h562.dtsi:391 */
			reg = < 0x40002000 0x400 >;     /* in zephyr/dts/arm/st/h5/stm32h562.dtsi:392 */
			clocks = < &rcc 0x9c 0x100 >;   /* in zephyr/dts/arm/st/h5/stm32h562.dtsi:393 */
			resets = < &rctl 0xe88 >;       /* in zephyr/dts/arm/st/h5/stm32h562.dtsi:394 */
			interrupts = < 0x7a 0x0 >;      /* in zephyr/dts/arm/st/h5/stm32h562.dtsi:395 */
			interrupt-names = "global";     /* in zephyr/dts/arm/st/h5/stm32h562.dtsi:396 */
			status = "disabled";            /* in zephyr/dts/arm/st/h5/stm32h562.dtsi:397 */

			/* node '/soc/timers@40002000/pwm' defined in zephyr/dts/arm/st/h5/stm32h562.dtsi:399 */
			pwm {
				compatible = "st,stm32-pwm"; /* in zephyr/dts/arm/st/h5/stm32h562.dtsi:400 */
				status = "disabled";         /* in zephyr/dts/arm/st/h5/stm32h562.dtsi:401 */
				#pwm-cells = < 0x3 >;        /* in zephyr/dts/arm/st/h5/stm32h562.dtsi:402 */
			};

			/* node '/soc/timers@40002000/counter' defined in zephyr/dts/arm/st/h5/stm32h562.dtsi:405 */
			counter {
				compatible = "st,stm32-counter"; /* in zephyr/dts/arm/st/h5/stm32h562.dtsi:406 */
				status = "disabled";             /* in zephyr/dts/arm/st/h5/stm32h562.dtsi:407 */
			};
		};

		/* node '/soc/timers@40014000' defined in zephyr/dts/arm/st/h5/stm32h562.dtsi:411 */
		timers15: timers@40014000 {
			compatible = "st,stm32-timers"; /* in zephyr/dts/arm/st/h5/stm32h562.dtsi:412 */
			reg = < 0x40014000 0x400 >;     /* in zephyr/dts/arm/st/h5/stm32h562.dtsi:413 */
			clocks = < &rcc 0xa4 0x10000 >; /* in zephyr/dts/arm/st/h5/stm32h562.dtsi:414 */
			resets = < &rctl 0xf90 >;       /* in zephyr/dts/arm/st/h5/stm32h562.dtsi:415 */
			interrupts = < 0x47 0x0 >;      /* in zephyr/dts/arm/st/h5/stm32h562.dtsi:416 */
			interrupt-names = "global";     /* in zephyr/dts/arm/st/h5/stm32h562.dtsi:417 */
			status = "disabled";            /* in zephyr/dts/arm/st/h5/stm32h562.dtsi:418 */

			/* node '/soc/timers@40014000/pwm' defined in zephyr/dts/arm/st/h5/stm32h562.dtsi:420 */
			pwm {
				compatible = "st,stm32-pwm"; /* in zephyr/dts/arm/st/h5/stm32h562.dtsi:421 */
				status = "disabled";         /* in zephyr/dts/arm/st/h5/stm32h562.dtsi:422 */
				#pwm-cells = < 0x3 >;        /* in zephyr/dts/arm/st/h5/stm32h562.dtsi:423 */
			};

			/* node '/soc/timers@40014000/counter' defined in zephyr/dts/arm/st/h5/stm32h562.dtsi:426 */
			counter {
				compatible = "st,stm32-counter"; /* in zephyr/dts/arm/st/h5/stm32h562.dtsi:427 */
				status = "disabled";             /* in zephyr/dts/arm/st/h5/stm32h562.dtsi:428 */
			};
		};

		/* node '/soc/timers@40014400' defined in zephyr/dts/arm/st/h5/stm32h562.dtsi:432 */
		timers16: timers@40014400 {
			compatible = "st,stm32-timers"; /* in zephyr/dts/arm/st/h5/stm32h562.dtsi:433 */
			reg = < 0x40014400 0x400 >;     /* in zephyr/dts/arm/st/h5/stm32h562.dtsi:434 */
			clocks = < &rcc 0xa4 0x20000 >; /* in zephyr/dts/arm/st/h5/stm32h562.dtsi:435 */
			resets = < &rctl 0xf91 >;       /* in zephyr/dts/arm/st/h5/stm32h562.dtsi:436 */
			interrupts = < 0x48 0x0 >;      /* in zephyr/dts/arm/st/h5/stm32h562.dtsi:437 */
			interrupt-names = "global";     /* in zephyr/dts/arm/st/h5/stm32h562.dtsi:438 */
			status = "disabled";            /* in zephyr/dts/arm/st/h5/stm32h562.dtsi:439 */

			/* node '/soc/timers@40014400/pwm' defined in zephyr/dts/arm/st/h5/stm32h562.dtsi:441 */
			pwm {
				compatible = "st,stm32-pwm"; /* in zephyr/dts/arm/st/h5/stm32h562.dtsi:442 */
				status = "disabled";         /* in zephyr/dts/arm/st/h5/stm32h562.dtsi:443 */
				#pwm-cells = < 0x3 >;        /* in zephyr/dts/arm/st/h5/stm32h562.dtsi:444 */
			};

			/* node '/soc/timers@40014400/counter' defined in zephyr/dts/arm/st/h5/stm32h562.dtsi:447 */
			counter {
				compatible = "st,stm32-counter"; /* in zephyr/dts/arm/st/h5/stm32h562.dtsi:448 */
				status = "disabled";             /* in zephyr/dts/arm/st/h5/stm32h562.dtsi:449 */
			};
		};

		/* node '/soc/timers@40014800' defined in zephyr/dts/arm/st/h5/stm32h562.dtsi:453 */
		timers17: timers@40014800 {
			compatible = "st,stm32-timers"; /* in zephyr/dts/arm/st/h5/stm32h562.dtsi:454 */
			reg = < 0x40014800 0x400 >;     /* in zephyr/dts/arm/st/h5/stm32h562.dtsi:455 */
			clocks = < &rcc 0xa4 0x40000 >; /* in zephyr/dts/arm/st/h5/stm32h562.dtsi:456 */
			resets = < &rctl 0xf92 >;       /* in zephyr/dts/arm/st/h5/stm32h562.dtsi:457 */
			interrupts = < 0x49 0x0 >;      /* in zephyr/dts/arm/st/h5/stm32h562.dtsi:458 */
			interrupt-names = "global";     /* in zephyr/dts/arm/st/h5/stm32h562.dtsi:459 */
			status = "disabled";            /* in zephyr/dts/arm/st/h5/stm32h562.dtsi:460 */

			/* node '/soc/timers@40014800/pwm' defined in zephyr/dts/arm/st/h5/stm32h562.dtsi:462 */
			pwm {
				compatible = "st,stm32-pwm"; /* in zephyr/dts/arm/st/h5/stm32h562.dtsi:463 */
				status = "disabled";         /* in zephyr/dts/arm/st/h5/stm32h562.dtsi:464 */
				#pwm-cells = < 0x3 >;        /* in zephyr/dts/arm/st/h5/stm32h562.dtsi:465 */
			};

			/* node '/soc/timers@40014800/counter' defined in zephyr/dts/arm/st/h5/stm32h562.dtsi:468 */
			counter {
				compatible = "st,stm32-counter"; /* in zephyr/dts/arm/st/h5/stm32h562.dtsi:469 */
				status = "disabled";             /* in zephyr/dts/arm/st/h5/stm32h562.dtsi:470 */
			};
		};

		/* node '/soc/aes@420c0000' defined in zephyr/dts/arm/st/h5/stm32h562.dtsi:474 */
		aes: aes@420c0000 {
			compatible = "st,stm32-aes";    /* in zephyr/dts/arm/st/h5/stm32h562.dtsi:475 */
			reg = < 0x420c0000 0x400 >;     /* in zephyr/dts/arm/st/h5/stm32h562.dtsi:476 */
			clocks = < &rcc 0x8c 0x10000 >; /* in zephyr/dts/arm/st/h5/stm32h562.dtsi:477 */
			resets = < &rctl 0xc90 >;       /* in zephyr/dts/arm/st/h5/stm32h562.dtsi:478 */
			interrupts = < 0x74 0x0 >;      /* in zephyr/dts/arm/st/h5/stm32h562.dtsi:479 */
			status = "disabled";            /* in zephyr/dts/arm/st/h5/stm32h562.dtsi:480 */
		};

		/* node '/soc/can@4000a800' defined in zephyr/dts/arm/st/h5/stm32h562.dtsi:483 */
		fdcan2: can@4000a800 {
			compatible = "st,stm32-fdcan";                           /* in zephyr/dts/arm/st/h5/stm32h562.dtsi:484 */
			reg = < 0x4000a800 0x400 >,
			      < 0x4000ac00 0x6a0 >;                              /* in zephyr/dts/arm/st/h5/stm32h562.dtsi:485 */
			reg-names = "m_can",
			            "message_ram";                               /* in zephyr/dts/arm/st/h5/stm32h562.dtsi:486 */
			interrupts = < 0x6d 0x0 >,
			             < 0x6e 0x0 >;                               /* in zephyr/dts/arm/st/h5/stm32h562.dtsi:487 */
			interrupt-names = "int0",
			                  "int1";                                /* in zephyr/dts/arm/st/h5/stm32h562.dtsi:488 */
			clocks = < &rcc 0xa0 0x200 >;                            /* in zephyr/dts/arm/st/h5/stm32h562.dtsi:490 */
			bosch,mram-cfg = < 0x350 0x1c 0x8 0x3 0x3 0x0 0x3 0x3 >; /* in zephyr/dts/arm/st/h5/stm32h562.dtsi:491 */
			status = "disabled";                                     /* in zephyr/dts/arm/st/h5/stm32h562.dtsi:492 */
		};

		/* node '/soc/sdmmc@46008000' defined in zephyr/dts/arm/st/h5/stm32h562.dtsi:495 */
		sdmmc1: sdmmc@46008000 {
			compatible = "st,stm32-sdmmc";  /* in zephyr/dts/arm/st/h5/stm32h562.dtsi:496 */
			reg = < 0x46008000 0x400 >;     /* in zephyr/dts/arm/st/h5/stm32h562.dtsi:497 */
			clocks = < &rcc 0x94 0x800 >,
			         < &rcc 0xd 0x4600e4 >; /* in zephyr/dts/arm/st/h5/stm32h562.dtsi:498 */
			resets = < &rctl 0xd8b >;       /* in zephyr/dts/arm/st/h5/stm32h562.dtsi:500 */
			interrupts = < 0x4f 0x0 >;      /* in zephyr/dts/arm/st/h5/stm32h562.dtsi:501 */
			status = "disabled";            /* in zephyr/dts/arm/st/h5/stm32h562.dtsi:502 */
		};

		/* node '/soc/memory-controller@47000400' defined in zephyr/dts/arm/st/h5/stm32h562.dtsi:505 */
		fmc: memory-controller@47000400 {
			compatible = "st,stm32-fmc";    /* in zephyr/dts/arm/st/h5/stm32h562.dtsi:506 */
			reg = < 0x47000400 0x400 >;     /* in zephyr/dts/arm/st/h5/stm32h562.dtsi:507 */
			clocks = < &rcc 0x94 0x10000 >; /* in zephyr/dts/arm/st/h5/stm32h562.dtsi:508 */
			status = "disabled";            /* in zephyr/dts/arm/st/h5/stm32h562.dtsi:509 */
		};

		/* node '/soc/sdmmc@46008c00' defined in zephyr/dts/arm/st/h5/stm32h563.dtsi:13 */
		sdmmc2: sdmmc@46008c00 {
			compatible = "st,stm32-sdmmc";  /* in zephyr/dts/arm/st/h5/stm32h563.dtsi:14 */
			reg = < 0x46008c00 0x400 >;     /* in zephyr/dts/arm/st/h5/stm32h563.dtsi:15 */
			clocks = < &rcc 0x94 0x1000 >,
			         < &rcc 0xd 0x4700e4 >; /* in zephyr/dts/arm/st/h5/stm32h563.dtsi:16 */
			resets = < &rctl 0xd8c >;       /* in zephyr/dts/arm/st/h5/stm32h563.dtsi:18 */
			interrupts = < 0x66 0x0 >;      /* in zephyr/dts/arm/st/h5/stm32h563.dtsi:19 */
			status = "disabled";            /* in zephyr/dts/arm/st/h5/stm32h563.dtsi:20 */
		};
	};

	/* node '/cpus' defined in zephyr/dts/arm/st/h5/stm32h5.dtsi:25 */
	cpus {
		#address-cells = < 0x1 >; /* in zephyr/dts/arm/st/h5/stm32h5.dtsi:26 */
		#size-cells = < 0x0 >;    /* in zephyr/dts/arm/st/h5/stm32h5.dtsi:27 */

		/* node '/cpus/cpu@0' defined in zephyr/dts/arm/st/h5/stm32h5.dtsi:29 */
		cpu0: cpu@0 {
			device_type = "cpu";           /* in zephyr/dts/arm/st/h5/stm32h5.dtsi:30 */
			compatible = "arm,cortex-m33"; /* in zephyr/dts/arm/st/h5/stm32h5.dtsi:31 */
			reg = < 0x0 >;                 /* in zephyr/dts/arm/st/h5/stm32h5.dtsi:32 */
			cpu-power-states = < &stop >;  /* in zephyr/dts/arm/st/h5/stm32h5.dtsi:33 */
			#address-cells = < 0x1 >;      /* in zephyr/dts/arm/st/h5/stm32h5.dtsi:34 */
			#size-cells = < 0x1 >;         /* in zephyr/dts/arm/st/h5/stm32h5.dtsi:35 */

			/* node '/cpus/cpu@0/mpu@e000ed90' defined in zephyr/dts/arm/st/h5/stm32h5.dtsi:37 */
			mpu: mpu@e000ed90 {
				compatible = "arm,armv8m-mpu"; /* in zephyr/dts/arm/st/h5/stm32h5.dtsi:38 */
				reg = < 0xe000ed90 0x40 >;     /* in zephyr/dts/arm/st/h5/stm32h5.dtsi:39 */
			};
		};

		/* node '/cpus/power-states' defined in zephyr/dts/arm/st/h5/stm32h5.dtsi:43 */
		power-states {

			/* node '/cpus/power-states/state0' defined in zephyr/dts/arm/st/h5/stm32h5.dtsi:44 */
			stop: state0 {
				compatible = "zephyr,power-state";    /* in zephyr/dts/arm/st/h5/stm32h5.dtsi:45 */
				power-state-name = "suspend-to-idle"; /* in zephyr/dts/arm/st/h5/stm32h5.dtsi:46 */
				substate-id = < 0x1 >;                /* in zephyr/dts/arm/st/h5/stm32h5.dtsi:47 */
				min-residency-us = < 0x14 >;          /* in zephyr/dts/arm/st/h5/stm32h5.dtsi:48 */
				phandle = < 0x25 >;                   /* in zephyr/dts/arm/st/h5/stm32h5.dtsi:33 */
			};
		};
	};

	/* node '/clocks' defined in zephyr/dts/arm/st/h5/stm32h5.dtsi:53 */
	clocks {

		/* node '/clocks/clk-hse' defined in zephyr/dts/arm/st/h5/stm32h5.dtsi:54 */
		clk_hse: clk-hse {
			#clock-cells = < 0x0 >;            /* in zephyr/dts/arm/st/h5/stm32h5.dtsi:55 */
			compatible = "st,stm32-hse-clock"; /* in zephyr/dts/arm/st/h5/stm32h5.dtsi:56 */
			clock-frequency = < 0x7a1200 >;    /* in zephyr/boards/st/nucleo_h563zi/nucleo_h563zi-common.dtsi:56 */
			hse-bypass;                        /* in zephyr/boards/st/nucleo_h563zi/nucleo_h563zi-common.dtsi:57 */
			status = "okay";                   /* in zephyr/boards/st/nucleo_h563zi/nucleo_h563zi-common.dtsi:58 */
			phandle = < 0x26 >;                /* in zephyr/boards/st/nucleo_h563zi/nucleo_h563zi-common.dtsi:75 */
		};

		/* node '/clocks/clk-hsi' defined in zephyr/dts/arm/st/h5/stm32h5.dtsi:60 */
		clk_hsi: clk-hsi {
			#clock-cells = < 0x0 >;              /* in zephyr/dts/arm/st/h5/stm32h5.dtsi:61 */
			compatible = "st,stm32h7-hsi-clock"; /* in zephyr/dts/arm/st/h5/stm32h5.dtsi:62 */
			hsi-div = < 0x1 >;                   /* in zephyr/dts/arm/st/h5/stm32h5.dtsi:63 */
			clock-frequency = < 0x3d09000 >;     /* in zephyr/dts/arm/st/h5/stm32h5.dtsi:64 */
			status = "disabled";                 /* in zephyr/dts/arm/st/h5/stm32h5.dtsi:65 */
		};

		/* node '/clocks/clk-hsi48' defined in zephyr/dts/arm/st/h5/stm32h5.dtsi:68 */
		clk_hsi48: clk-hsi48 {
			#clock-cells = < 0x0 >;          /* in zephyr/dts/arm/st/h5/stm32h5.dtsi:69 */
			compatible = "fixed-clock";      /* in zephyr/dts/arm/st/h5/stm32h5.dtsi:70 */
			clock-frequency = < 0x2dc6c00 >; /* in zephyr/dts/arm/st/h5/stm32h5.dtsi:71 */
			status = "okay";                 /* in zephyr/boards/st/nucleo_h563zi/nucleo_h563zi-common.dtsi:62 */
		};

		/* node '/clocks/clk-csi' defined in zephyr/dts/arm/st/h5/stm32h5.dtsi:75 */
		clk_csi: clk-csi {
			#clock-cells = < 0x0 >;         /* in zephyr/dts/arm/st/h5/stm32h5.dtsi:76 */
			compatible = "fixed-clock";     /* in zephyr/dts/arm/st/h5/stm32h5.dtsi:77 */
			clock-frequency = < 0x3d0900 >; /* in zephyr/dts/arm/st/h5/stm32h5.dtsi:78 */
			status = "disabled";            /* in zephyr/dts/arm/st/h5/stm32h5.dtsi:79 */
		};

		/* node '/clocks/clk-lse' defined in zephyr/dts/arm/st/h5/stm32h5.dtsi:82 */
		clk_lse: clk-lse {
			#clock-cells = < 0x0 >;            /* in zephyr/dts/arm/st/h5/stm32h5.dtsi:83 */
			compatible = "st,stm32-lse-clock"; /* in zephyr/dts/arm/st/h5/stm32h5.dtsi:84 */
			clock-frequency = < 0x8000 >;      /* in zephyr/dts/arm/st/h5/stm32h5.dtsi:85 */
			driving-capability = < 0x2 >;      /* in zephyr/dts/arm/st/h5/stm32h5.dtsi:86 */
			status = "okay";                   /* in zephyr/boards/st/nucleo_h563zi/nucleo_h563zi-common.dtsi:66 */
		};

		/* node '/clocks/clk-lsi' defined in zephyr/dts/arm/st/h5/stm32h5.dtsi:90 */
		clk_lsi: clk-lsi {
			#clock-cells = < 0x0 >;       /* in zephyr/dts/arm/st/h5/stm32h5.dtsi:91 */
			compatible = "fixed-clock";   /* in zephyr/dts/arm/st/h5/stm32h5.dtsi:92 */
			clock-frequency = < 0x7d00 >; /* in zephyr/dts/arm/st/h5/stm32h5.dtsi:93 */
			status = "okay";              /* in zephyr/boards/st/nucleo_h563zi/nucleo_h563zi-common.dtsi:220 */
		};

		/* node '/clocks/pll' defined in zephyr/dts/arm/st/h5/stm32h5.dtsi:97 */
		pll1: pll: pll {
			#clock-cells = < 0x0 >;              /* in zephyr/dts/arm/st/h5/stm32h5.dtsi:98 */
			compatible = "st,stm32u5-pll-clock"; /* in zephyr/dts/arm/st/h5/stm32h5.dtsi:99 */
			div-m = < 0x2 >;                     /* in zephyr/boards/st/nucleo_h563zi/nucleo_h563zi-common.dtsi:70 */
			mul-n = < 0x78 >;                    /* in zephyr/boards/st/nucleo_h563zi/nucleo_h563zi-common.dtsi:71 */
			div-p = < 0x2 >;                     /* in zephyr/boards/st/nucleo_h563zi/nucleo_h563zi-common.dtsi:72 */
			div-q = < 0x3 >;                     /* in zephyr/boards/st/nucleo_h563zi/nucleo_h563zi-common.dtsi:73 */
			div-r = < 0x2 >;                     /* in zephyr/boards/st/nucleo_h563zi/nucleo_h563zi-common.dtsi:74 */
			clocks = < &clk_hse >;               /* in zephyr/boards/st/nucleo_h563zi/nucleo_h563zi-common.dtsi:75 */
			status = "okay";                     /* in zephyr/boards/st/nucleo_h563zi/nucleo_h563zi-common.dtsi:76 */
			phandle = < 0x3 >;                   /* in zephyr/boards/st/nucleo_h563zi/nucleo_h563zi-common.dtsi:93 */
		};

		/* node '/clocks/pll2' defined in zephyr/dts/arm/st/h5/stm32h5.dtsi:103 */
		pll2: pll2 {
			#clock-cells = < 0x0 >;              /* in zephyr/dts/arm/st/h5/stm32h5.dtsi:104 */
			compatible = "st,stm32u5-pll-clock"; /* in zephyr/dts/arm/st/h5/stm32h5.dtsi:105 */
			status = "disabled";                 /* in zephyr/dts/arm/st/h5/stm32h5.dtsi:106 */
		};

		/* node '/clocks/pll3' defined in zephyr/dts/arm/st/h5/stm32h562.dtsi:16 */
		pll3: pll3 {
			#clock-cells = < 0x0 >;              /* in zephyr/dts/arm/st/h5/stm32h562.dtsi:17 */
			compatible = "st,stm32u5-pll-clock"; /* in zephyr/dts/arm/st/h5/stm32h562.dtsi:18 */
			status = "disabled";                 /* in zephyr/dts/arm/st/h5/stm32h562.dtsi:19 */
		};
	};

	/* node '/mcos' defined in zephyr/dts/arm/st/h5/stm32h5.dtsi:110 */
	mcos {

		/* node '/mcos/mco1' defined in zephyr/dts/arm/st/h5/stm32h5.dtsi:111 */
		mco1: mco1 {
			compatible = "st,stm32-clock-mco"; /* in zephyr/dts/arm/st/h5/stm32h5.dtsi:112 */
			status = "disabled";               /* in zephyr/dts/arm/st/h5/stm32h5.dtsi:113 */
		};

		/* node '/mcos/mco2' defined in zephyr/dts/arm/st/h5/stm32h5.dtsi:116 */
		mco2: mco2 {
			compatible = "st,stm32-clock-mco"; /* in zephyr/dts/arm/st/h5/stm32h5.dtsi:117 */
			status = "disabled";               /* in zephyr/dts/arm/st/h5/stm32h5.dtsi:118 */
		};
	};

	/* node '/dietemp' defined in zephyr/dts/arm/st/h5/stm32h5.dtsi:683 */
	die_temp: dietemp {
		compatible = "st,stm32-temp-cal"; /* in zephyr/dts/arm/st/h5/stm32h5.dtsi:684 */
		ts-cal1-addr = < 0x8fff814 >;     /* in zephyr/dts/arm/st/h5/stm32h5.dtsi:685 */
		ts-cal2-addr = < 0x8fff818 >;     /* in zephyr/dts/arm/st/h5/stm32h5.dtsi:686 */
		ts-cal1-temp = < 0x1e >;          /* in zephyr/dts/arm/st/h5/stm32h5.dtsi:687 */
		ts-cal2-temp = < 0x82 >;          /* in zephyr/dts/arm/st/h5/stm32h5.dtsi:688 */
		ts-cal-vrefanalog = < 0xce4 >;    /* in zephyr/dts/arm/st/h5/stm32h5.dtsi:689 */
		ts-cal-resolution = < 0xc >;      /* in zephyr/dts/arm/st/h5/stm32h5.dtsi:690 */
		io-channels = < &adc1 0x10 >;     /* in zephyr/dts/arm/st/h5/stm32h5.dtsi:691 */
		status = "disabled";              /* in zephyr/dts/arm/st/h5/stm32h5.dtsi:692 */
	};

	/* node '/vref' defined in zephyr/dts/arm/st/h5/stm32h5.dtsi:695 */
	vref: vref {
		compatible = "st,stm32-vref";     /* in zephyr/dts/arm/st/h5/stm32h5.dtsi:696 */
		vrefint-cal-addr = < 0x8fff810 >; /* in zephyr/dts/arm/st/h5/stm32h5.dtsi:697 */
		vrefint-cal-mv = < 0xce4 >;       /* in zephyr/dts/arm/st/h5/stm32h5.dtsi:698 */
		io-channels = < &adc1 0x11 >;     /* in zephyr/dts/arm/st/h5/stm32h5.dtsi:699 */
		status = "okay";                  /* in zephyr/boards/st/nucleo_h563zi/nucleo_h563zi-common.dtsi:212 */
	};

	/* node '/vbat' defined in zephyr/dts/arm/st/h5/stm32h5.dtsi:703 */
	vbat: vbat {
		compatible = "st,stm32-vbat"; /* in zephyr/dts/arm/st/h5/stm32h5.dtsi:704 */
		ratio = < 0x4 >;              /* in zephyr/dts/arm/st/h5/stm32h5.dtsi:705 */
		io-channels = < &adc1 0x2 >;  /* in zephyr/dts/arm/st/h5/stm32h5.dtsi:706 */
		status = "okay";              /* in zephyr/boards/st/nucleo_h563zi/nucleo_h563zi-common.dtsi:216 */
	};

	/* node '/usbphy' defined in zephyr/dts/arm/st/h5/stm32h5.dtsi:710 */
	usb_fs_phy: usbphy {
		compatible = "usb-nop-xceiv"; /* in zephyr/dts/arm/st/h5/stm32h5.dtsi:711 */
		#phy-cells = < 0x0 >;         /* in zephyr/dts/arm/st/h5/stm32h5.dtsi:712 */
		phandle = < 0x22 >;           /* in zephyr/dts/arm/st/h5/stm32h5.dtsi:667 */
	};

	/* node '/smbus1' defined in zephyr/dts/arm/st/h5/stm32h5.dtsi:715 */
	smbus1: smbus1 {
		compatible = "st,stm32-smbus"; /* in zephyr/dts/arm/st/h5/stm32h5.dtsi:716 */
		#address-cells = < 0x1 >;      /* in zephyr/dts/arm/st/h5/stm32h5.dtsi:717 */
		#size-cells = < 0x0 >;         /* in zephyr/dts/arm/st/h5/stm32h5.dtsi:718 */
		i2c = < &i2c1 >;               /* in zephyr/dts/arm/st/h5/stm32h5.dtsi:719 */
		status = "disabled";           /* in zephyr/dts/arm/st/h5/stm32h5.dtsi:720 */
	};

	/* node '/smbus2' defined in zephyr/dts/arm/st/h5/stm32h5.dtsi:723 */
	smbus2: smbus2 {
		compatible = "st,stm32-smbus"; /* in zephyr/dts/arm/st/h5/stm32h5.dtsi:724 */
		#address-cells = < 0x1 >;      /* in zephyr/dts/arm/st/h5/stm32h5.dtsi:725 */
		#size-cells = < 0x0 >;         /* in zephyr/dts/arm/st/h5/stm32h5.dtsi:726 */
		i2c = < &i2c2 >;               /* in zephyr/dts/arm/st/h5/stm32h5.dtsi:727 */
		status = "disabled";           /* in zephyr/dts/arm/st/h5/stm32h5.dtsi:728 */
	};

	/* node '/smbus3' defined in zephyr/dts/arm/st/h5/stm32h562.dtsi:513 */
	smbus3: smbus3 {
		compatible = "st,stm32-smbus"; /* in zephyr/dts/arm/st/h5/stm32h562.dtsi:514 */
		#address-cells = < 0x1 >;      /* in zephyr/dts/arm/st/h5/stm32h562.dtsi:515 */
		#size-cells = < 0x0 >;         /* in zephyr/dts/arm/st/h5/stm32h562.dtsi:516 */
		i2c = < &i2c3 >;               /* in zephyr/dts/arm/st/h5/stm32h562.dtsi:517 */
		status = "disabled";           /* in zephyr/dts/arm/st/h5/stm32h562.dtsi:518 */
	};

	/* node '/smbus4' defined in zephyr/dts/arm/st/h5/stm32h562.dtsi:521 */
	smbus4: smbus4 {
		compatible = "st,stm32-smbus"; /* in zephyr/dts/arm/st/h5/stm32h562.dtsi:522 */
		#address-cells = < 0x1 >;      /* in zephyr/dts/arm/st/h5/stm32h562.dtsi:523 */
		#size-cells = < 0x0 >;         /* in zephyr/dts/arm/st/h5/stm32h562.dtsi:524 */
		i2c = < &i2c4 >;               /* in zephyr/dts/arm/st/h5/stm32h562.dtsi:525 */
		status = "disabled";           /* in zephyr/dts/arm/st/h5/stm32h562.dtsi:526 */
	};

	/* node '/connector' defined in zephyr/boards/st/nucleo_h563zi/arduino_r3_connector.dtsi:9 */
	arduino_header: connector {
		compatible = "arduino-header-r3";          /* in zephyr/boards/st/nucleo_h563zi/arduino_r3_connector.dtsi:10 */
		#gpio-cells = < 0x2 >;                     /* in zephyr/boards/st/nucleo_h563zi/arduino_r3_connector.dtsi:11 */
		gpio-map-mask = < 0xffffffff 0xffffffc0 >; /* in zephyr/boards/st/nucleo_h563zi/arduino_r3_connector.dtsi:12 */
		gpio-map-pass-thru = < 0x0 0x3f >;         /* in zephyr/boards/st/nucleo_h563zi/arduino_r3_connector.dtsi:13 */
		gpio-map = < 0x0 0x0 &gpioa 0x6 0x0 >,
		           < 0x1 0x0 &gpioc 0x0 0x0 >,
		           < 0x2 0x0 &gpioc 0x3 0x0 >,
		           < 0x3 0x0 &gpiob 0x1 0x0 >,
		           < 0x4 0x0 &gpioc 0x2 0x0 >,
		           < 0x5 0x0 &gpiof 0xb 0x0 >,
		           < 0x6 0x0 &gpiob 0x7 0x0 >,
		           < 0x7 0x0 &gpiob 0x6 0x0 >,
		           < 0x8 0x0 &gpiog 0xe 0x0 >,
		           < 0x9 0x0 &gpioe 0xd 0x0 >,
		           < 0xa 0x0 &gpioe 0xe 0x0 >,
		           < 0xb 0x0 &gpioe 0xb 0x0 >,
		           < 0xc 0x0 &gpioe 0x9 0x0 >,
		           < 0xd 0x0 &gpiog 0xc 0x0 >,
		           < 0xe 0x0 &gpiof 0x3 0x0 >,
		           < 0xf 0x0 &gpiod 0xf 0x0 >,
		           < 0x10 0x0 &gpiod 0xe 0x0 >,
		           < 0x11 0x0 &gpiob 0x5 0x0 >,
		           < 0x12 0x0 &gpiog 0x9 0x0 >,
		           < 0x13 0x0 &gpioa 0x5 0x0 >,
		           < 0x14 0x0 &gpiob 0x9 0x0 >,
		           < 0x15 0x0 &gpiob 0x8 0x0 >;    /* in zephyr/boards/st/nucleo_h563zi/arduino_r3_connector.dtsi:14 */
	};

	/* node '/st-morpho-header' defined in zephyr/boards/st/nucleo_h563zi/st_morpho_connector.dtsi:10 */
	st_morpho_header: st-morpho-header {
		compatible = "st-morpho-header";        /* in zephyr/boards/st/nucleo_h563zi/st_morpho_connector.dtsi:11 */
		#gpio-cells = < 0x2 >;                  /* in zephyr/boards/st/nucleo_h563zi/st_morpho_connector.dtsi:12 */
		gpio-map-mask = < 0xff 0x0 >;           /* in zephyr/boards/st/nucleo_h563zi/st_morpho_connector.dtsi:13 */
		gpio-map-pass-thru = < 0x0 0x3f >;      /* in zephyr/boards/st/nucleo_h563zi/st_morpho_connector.dtsi:14 */
		gpio-map = < 0x0 0x0 &gpioc 0xa 0x0 >,
		           < 0x1 0x0 &gpioc 0xb 0x0 >,
		           < 0x2 0x0 &gpioc 0xc 0x0 >,
		           < 0x3 0x0 &gpiod 0x2 0x0 >,
		           < 0x8 0x0 &gpiof 0x6 0x0 >,
		           < 0xa 0x0 &gpiof 0x7 0x0 >,
		           < 0xc 0x0 &gpioa 0xd 0x0 >,
		           < 0xe 0x0 &gpioa 0xe 0x0 >,
		           < 0x10 0x0 &gpioa 0xf 0x0 >,
		           < 0x14 0x0 &gpiob 0x7 0x0 >,
		           < 0x16 0x0 &gpioc 0xd 0x0 >,
		           < 0x18 0x0 &gpioc 0xe 0x0 >,
		           < 0x1a 0x0 &gpioc 0xf 0x0 >,
		           < 0x1b 0x0 &gpioa 0x0 0x0 >,
		           < 0x1c 0x0 &gpioh 0x0 0x0 >,
		           < 0x1d 0x0 &gpioa 0x1 0x0 >,
		           < 0x1e 0x0 &gpioh 0x1 0x0 >,
		           < 0x1f 0x0 &gpioa 0x4 0x0 >,
		           < 0x21 0x0 &gpiob 0x0 0x0 >,
		           < 0x22 0x0 &gpioc 0x2 0x0 >,
		           < 0x23 0x0 &gpioc 0x1 0x0 >,
		           < 0x24 0x0 &gpioc 0x3 0x0 >,
		           < 0x25 0x0 &gpioc 0x0 0x0 >,
		           < 0x26 0x0 &gpiod 0x4 0x0 >,
		           < 0x27 0x0 &gpiod 0x3 0x0 >,
		           < 0x28 0x0 &gpiod 0x5 0x0 >,
		           < 0x29 0x0 &gpiog 0x2 0x0 >,
		           < 0x2a 0x0 &gpiod 0x6 0x0 >,
		           < 0x2b 0x0 &gpiog 0x3 0x0 >,
		           < 0x2c 0x0 &gpiod 0x7 0x0 >,
		           < 0x2d 0x0 &gpioe 0x2 0x0 >,
		           < 0x2e 0x0 &gpioe 0x3 0x0 >,
		           < 0x2f 0x0 &gpioe 0x4 0x0 >,
		           < 0x31 0x0 &gpioe 0x5 0x0 >,
		           < 0x32 0x0 &gpiof 0x1 0x0 >,
		           < 0x33 0x0 &gpiof 0x2 0x0 >,
		           < 0x34 0x0 &gpiof 0x0 0x0 >,
		           < 0x35 0x0 &gpiof 0x8 0x0 >,
		           < 0x36 0x0 &gpiod 0x1 0x0 >,
		           < 0x37 0x0 &gpiof 0x9 0x0 >,
		           < 0x38 0x0 &gpiod 0x0 0x0 >,
		           < 0x39 0x0 &gpiog 0x1 0x0 >,
		           < 0x3a 0x0 &gpiog 0x0 0x0 >,
		           < 0x3d 0x0 &gpioe 0x6 0x0 >,
		           < 0x3e 0x0 &gpiog 0x9 0x0 >,
		           < 0x3f 0x0 &gpiog 0xf 0x0 >,
		           < 0x40 0x0 &gpiog 0xc 0x0 >,
		           < 0x41 0x0 &gpiog 0xa 0x0 >,
		           < 0x43 0x0 &gpiog 0xd 0x0 >,
		           < 0x44 0x0 &gpiod 0x9 0x0 >,
		           < 0x45 0x0 &gpiog 0xb 0x0 >,
		           < 0x48 0x0 &gpioc 0x9 0x0 >,
		           < 0x49 0x0 &gpioc 0x8 0x0 >,
		           < 0x4a 0x0 &gpiob 0x8 0x0 >,
		           < 0x4b 0x0 &gpioc 0x6 0x0 >,
		           < 0x4c 0x0 &gpiob 0x9 0x0 >,
		           < 0x4d 0x0 &gpioc 0x5 0x0 >,
		           < 0x51 0x0 &gpiod 0x8 0x0 >,
		           < 0x52 0x0 &gpioa 0x5 0x0 >,
		           < 0x53 0x0 &gpioa 0xc 0x0 >,
		           < 0x54 0x0 &gpioa 0x6 0x0 >,
		           < 0x55 0x0 &gpioa 0xb 0x0 >,
		           < 0x56 0x0 &gpioa 0x7 0x0 >,
		           < 0x57 0x0 &gpiob 0xc 0x0 >,
		           < 0x58 0x0 &gpiob 0x6 0x0 >,
		           < 0x5a 0x0 &gpioc 0x7 0x0 >,
		           < 0x5c 0x0 &gpioa 0x9 0x0 >,
		           < 0x5d 0x0 &gpiob 0x2 0x0 >,
		           < 0x5e 0x0 &gpioa 0x8 0x0 >,
		           < 0x5f 0x0 &gpiob 0x1 0x0 >,
		           < 0x60 0x0 &gpiob 0xa 0x0 >,
		           < 0x61 0x0 &gpiob 0xf 0x0 >,
		           < 0x62 0x0 &gpiob 0x4 0x0 >,
		           < 0x63 0x0 &gpiob 0xe 0x0 >,
		           < 0x64 0x0 &gpiob 0x5 0x0 >,
		           < 0x65 0x0 &gpiob 0xd 0x0 >,
		           < 0x66 0x0 &gpiob 0x3 0x0 >,
		           < 0x68 0x0 &gpioa 0xa 0x0 >,
		           < 0x69 0x0 &gpioc 0x4 0x0 >,
		           < 0x6a 0x0 &gpioa 0x2 0x0 >,
		           < 0x6b 0x0 &gpiof 0x5 0x0 >,
		           < 0x6c 0x0 &gpioa 0x3 0x0 >,
		           < 0x6d 0x0 &gpiof 0x4 0x0 >,
		           < 0x6f 0x0 &gpioe 0x8 0x0 >,
		           < 0x70 0x0 &gpiod 0xd 0x0 >,
		           < 0x71 0x0 &gpiof 0xa 0x0 >,
		           < 0x72 0x0 &gpiod 0xc 0x0 >,
		           < 0x73 0x0 &gpioe 0x7 0x0 >,
		           < 0x74 0x0 &gpiod 0xb 0x0 >,
		           < 0x75 0x0 &gpiod 0xe 0x0 >,
		           < 0x76 0x0 &gpioe 0xa 0x0 >,
		           < 0x77 0x0 &gpiod 0xf 0x0 >,
		           < 0x78 0x0 &gpioe 0xc 0x0 >,
		           < 0x79 0x0 &gpiof 0xe 0x0 >,
		           < 0x7a 0x0 &gpioe 0xe 0x0 >,
		           < 0x7b 0x0 &gpioe 0x9 0x0 >,
		           < 0x7c 0x0 &gpioe 0xf 0x0 >,
		           < 0x7e 0x0 &gpioe 0xd 0x0 >,
		           < 0x7f 0x0 &gpioe 0xb 0x0 >,
		           < 0x80 0x0 &gpiof 0xd 0x0 >,
		           < 0x81 0x0 &gpiof 0x3 0x0 >,
		           < 0x82 0x0 &gpiof 0xc 0x0 >,
		           < 0x83 0x0 &gpiof 0xf 0x0 >,
		           < 0x84 0x0 &gpiog 0xe 0x0 >,
		           < 0x85 0x0 &gpiof 0xb 0x0 >,
		           < 0x87 0x0 &gpioe 0x0 0x0 >,
		           < 0x88 0x0 &gpiod 0xa 0x0 >,
		           < 0x89 0x0 &gpiog 0x8 0x0 >,
		           < 0x8a 0x0 &gpiog 0x7 0x0 >,
		           < 0x8b 0x0 &gpiog 0x5 0x0 >,
		           < 0x8c 0x0 &gpiog 0x4 0x0 >,
		           < 0x8d 0x0 &gpiog 0x6 0x0 >; /* in zephyr/boards/st/nucleo_h563zi/st_morpho_connector.dtsi:15 */
	};

	/* node '/leds' defined in zephyr/boards/st/nucleo_h563zi/nucleo_h563zi-common.dtsi:15 */
	leds: leds {
		compatible = "gpio-leds"; /* in zephyr/boards/st/nucleo_h563zi/nucleo_h563zi-common.dtsi:16 */

		/* node '/leds/led_1' defined in zephyr/boards/st/nucleo_h563zi/nucleo_h563zi-common.dtsi:18 */
		green_led_1: led_1 {
			gpios = < &gpiob 0x0 0x0 >; /* in zephyr/boards/st/nucleo_h563zi/nucleo_h563zi-common.dtsi:19 */
			label = "User LD1";         /* in zephyr/boards/st/nucleo_h563zi/nucleo_h563zi-common.dtsi:20 */
		};

		/* node '/leds/led_2' defined in zephyr/boards/st/nucleo_h563zi/nucleo_h563zi-common.dtsi:23 */
		yellow_led_1: led_2 {
			gpios = < &gpiof 0x4 0x0 >; /* in zephyr/boards/st/nucleo_h563zi/nucleo_h563zi-common.dtsi:24 */
			label = "User LD2";         /* in zephyr/boards/st/nucleo_h563zi/nucleo_h563zi-common.dtsi:25 */
		};

		/* node '/leds/led_3' defined in zephyr/boards/st/nucleo_h563zi/nucleo_h563zi-common.dtsi:28 */
		red_led_1: led_3 {
			gpios = < &gpiog 0x4 0x0 >; /* in zephyr/boards/st/nucleo_h563zi/nucleo_h563zi-common.dtsi:29 */
			label = "User LD3";         /* in zephyr/boards/st/nucleo_h563zi/nucleo_h563zi-common.dtsi:30 */
		};
	};

	/* node '/gpio_keys' defined in zephyr/boards/st/nucleo_h563zi/nucleo_h563zi-common.dtsi:34 */
	gpio_keys {
		compatible = "gpio-keys"; /* in zephyr/boards/st/nucleo_h563zi/nucleo_h563zi-common.dtsi:35 */

		/* node '/gpio_keys/button' defined in zephyr/boards/st/nucleo_h563zi/nucleo_h563zi-common.dtsi:37 */
		user_button: button {
			label = "User";             /* in zephyr/boards/st/nucleo_h563zi/nucleo_h563zi-common.dtsi:38 */
			gpios = < &gpioc 0xd 0x0 >; /* in zephyr/boards/st/nucleo_h563zi/nucleo_h563zi-common.dtsi:39 */
			zephyr,code = < 0xb >;      /* in zephyr/boards/st/nucleo_h563zi/nucleo_h563zi-common.dtsi:40 */
		};
	};

	/* node '/pwmleds' defined in zephyr/boards/st/nucleo_h563zi/nucleo_h563zi-common.dtsi:44 */
	pwmleds: pwmleds {
		compatible = "pwm-leds"; /* in zephyr/boards/st/nucleo_h563zi/nucleo_h563zi-common.dtsi:45 */
		status = "disabled";     /* in zephyr/boards/st/nucleo_h563zi/nucleo_h563zi-common.dtsi:46 */

		/* node '/pwmleds/green_led_1' defined in zephyr/boards/st/nucleo_h563zi/nucleo_h563zi-common.dtsi:48 */
		pwm_led_1: green_led_1 {
			pwms = < &pwm3 0x3 0x1312d00 0x0 >; /* in zephyr/boards/st/nucleo_h563zi/nucleo_h563zi-common.dtsi:49 */
			label = "green led";                /* in zephyr/boards/st/nucleo_h563zi/nucleo_h563zi-common.dtsi:50 */
		};
	};
};
